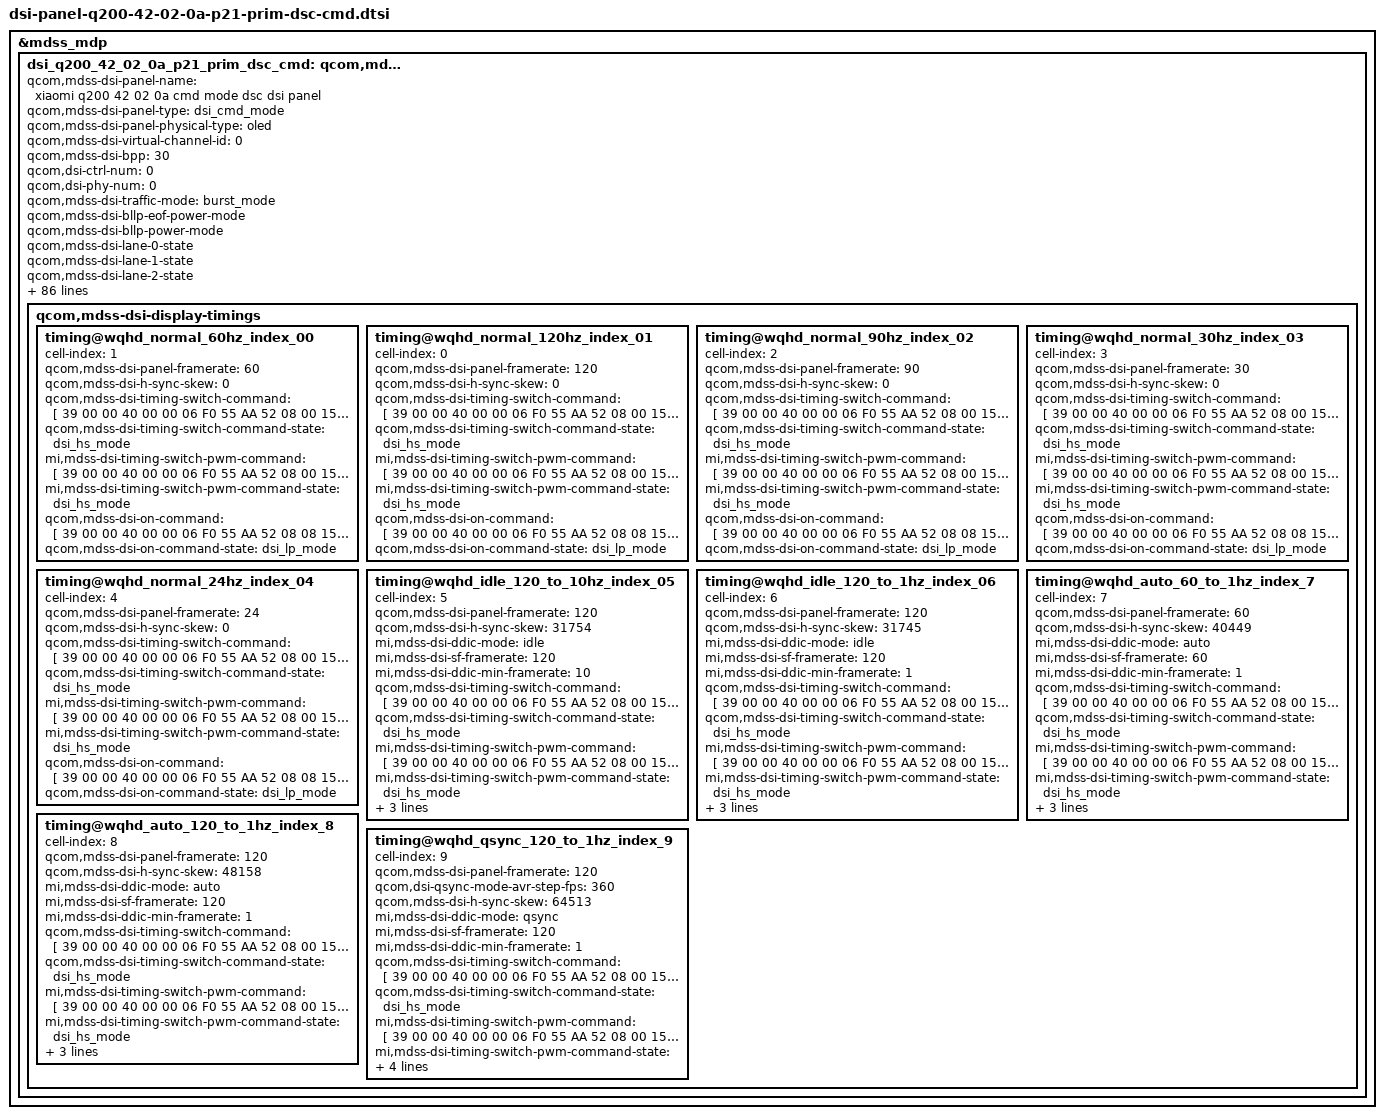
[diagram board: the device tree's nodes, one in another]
&mdss_mdp {
	dsi_q200_42_02_0a_p21_prim_dsc_cmd: qcom,mdss_dsi_q200_42_02_0a_p21_prim_dsc_cmd {
		qcom,mdss-dsi-panel-name = "xiaomi q200 42 02 0a cmd mode dsc dsi panel";
		qcom,mdss-dsi-panel-type = "dsi_cmd_mode";
		qcom,mdss-dsi-panel-physical-type = "oled";
		qcom,mdss-dsi-virtual-channel-id = <0>;
		qcom,mdss-dsi-bpp = <30>;
		qcom,dsi-ctrl-num = <0>;
		qcom,dsi-phy-num = <0>;
		qcom,mdss-dsi-traffic-mode = "burst_mode";
		qcom,mdss-dsi-bllp-eof-power-mode;
		qcom,mdss-dsi-bllp-power-mode;
		qcom,mdss-dsi-lane-0-state;
		qcom,mdss-dsi-lane-1-state;
		qcom,mdss-dsi-lane-2-state;
		qcom,mdss-dsi-lane-3-state;
		qcom,mdss-dsi-color-order = "rgb_swap_rgb";
		qcom,mdss-dsi-dma-trigger = "trigger_sw";
		qcom,mdss-dsi-mdp-trigger = "none";
		qcom,mdss-dsi-reset-sequence =<1 1>, <0 1>, <1 10>;
		qcom,mdss-pan-physical-width-dimension = <673>;
		qcom,mdss-pan-physical-height-dimension = <1466>;
		qcom,mdss-dsi-te-pin-select = <1>;
		qcom,mdss-dsi-wr-mem-start = <0x2c>;
		qcom,mdss-dsi-wr-mem-continue = <0x3c>;
		qcom,mdss-dsi-te-dcs-command = <1>;
		qcom,mdss-dsi-tx-eot-append;
		qcom,mdss-dsi-lp11-init;
		qcom,mdss-dsi-bl-inverted-dbv;
		qcom,bl-update-flag = "delay_until_first_frame";
		qcom,mdss-dsi-panel-hdr-enabled;
		qcom,mdss-dsi-panel-hdr-color-primaries = <14500 15500 32000
			17000 15500 30000 8000 3000>;
		qcom,mdss-dsi-panel-peak-brightness = <32000000>;
		qcom,mdss-dsi-panel-blackness-level = <3230>;
		qcom,mdss-dsi-dma-schedule-line = <1>;
		qcom,mdss-dsi-dma-schedule-window = <50>;

		qcom,spr-pack-type = "pentile";
		/*
		 *###############################################################
		 * # Pentile SPR phases for SM8850 and later
		 *###############################################################
		 * # RG/BG Type A    BG/RG Type A    GR/GB Type A    GB/GR Type A
		 * # R B R B ...     B R B R ...      R B R B ...     B R B R ...
		 * #  G G G G ...     G G G G ...    G G G G ...     G G G G ...
		 * #
		 * # RG/BG Type B    BG/RG Type B    GR/GB Type B    GB/GR Type B
		 * #  G G G G ...     G G G G ...    G G G G ...     G G G G ...
		 * # R B R B ...     B R B R ...      R B R B ...     B R B R ...
		 *###############################################################
		 */
		qcom,spr-pentile-pack-type = "BG-RG Type A";

		qcom,mdss-disable-cesta-hw-sleep;

		qcom,mdss-dsi-display-timings {
			timing@wqhd_normal_60hz_index_00 {
				#include "dsi-panel-q200-42-02-0a-p21-prim-dsc-cmd-common.dtsi"
				cell-index = <1>;
				qcom,mdss-dsi-panel-framerate = <60>;
				qcom,mdss-dsi-h-sync-skew = <0>;
				qcom,mdss-dsi-timing-switch-command = [
					// Fix 60hz Temp
					39 00 00 40 00 00 06 F0 55 AA 52 08 00
					15 00 00 40 00 00 02 6F 0E
					15 00 00 40 00 00 02 C0 00
					15 00 00 40 00 00 02 6F DE
					15 00 00 40 00 00 02 BA 04
					15 00 00 40 00 00 02 6F 04
					15 00 00 40 00 00 02 35 01
					15 00 00 40 00 00 02 6F 14
					15 00 00 40 00 00 02 35 00
					39 00 00 40 00 00 03 44 0A 60
					15 00 00 40 00 00 02 8C 02
					15 00 00 00 00 00 02 6D 02
				];
				qcom,mdss-dsi-timing-switch-command-state = "dsi_hs_mode";
				mi,mdss-dsi-timing-switch-pwm-command = [
					// Fix 60hz Temp
					39 00 00 40 00 00 06 F0 55 AA 52 08 00
					15 00 00 40 00 00 02 6F 0E
					15 00 00 40 00 00 02 C0 00
					15 00 00 40 00 00 02 6F DE
					15 00 00 40 00 00 02 BA 04
					15 00 00 40 00 00 02 6F 04
					15 00 00 40 00 00 02 35 01
					15 00 00 40 00 00 02 6F 14
					15 00 00 40 00 00 02 35 00
					39 00 00 40 00 00 03 44 0A 60
					15 00 00 40 00 00 02 8C 02
					15 00 00 00 00 00 02 6D 02
				];
				mi,mdss-dsi-timing-switch-pwm-command-state = "dsi_hs_mode";
				qcom,mdss-dsi-on-command = [
					// LCTC ON
					39 00 00 40 00 00 06 F0 55 AA 52 08 08
					15 00 00 40 00 00 02 BF 21
					// ACTC ON
					15 00 00 40 00 00 02 6F B7
					15 00 00 00 00 00 02 BF 11
					// OD ON
					39 00 00 40 00 00 06 F0 55 AA 52 08 08
					15 00 00 00 00 00 02 E0 01
					// VINT power domain
					39 00 00 40 00 00 06 F0 55 AA 52 08 01
					15 00 00 40 00 00 02 6F 49
					39 00 00 00 00 00 06 B9 01 22 00 EE EE
					// AOD pump
					39 00 00 40 00 00 06 F0 55 AA 52 08 01
					39 00 00 00 00 00 05 B2 00 00 FF 03
					// Data chopper setting
					39 00 00 40 00 00 06 F0 55 AA 52 08 01
					15 00 00 40 00 00 02 6F 23
					39 00 00 00 00 00 04 D9 CB 49 13
					// EM TH2 Duty Setting
					39 00 00 40 00 00 06 F0 55 AA 52 08 00
					39 00 00 40 00 00 02 6F 21
					39 00 00 40 00 00 09 B2 00 28 00 28 00 3C 00 28
					39 00 00 40 00 00 02 6F 75
					39 00 00 40 00 00 09 B2 00 28 00 28 00 3C 00 28
					39 00 00 40 00 00 02 6F 71
					39 00 00 00 00 00 03 B2 00 28
					// PMIC Fast discharge
					39 00 00 40 00 00 02 6F 51
					39 00 00 40 00 00 02 D5 02
					39 00 00 40 00 00 02 6F 54
					39 00 00 00 00 00 02 D5 1F
					// Switch VGMP by Fcon
					39 00 00 40 00 00 06 F0 55 AA 52 08 01
					39 00 00 40 00 00 02 6F 16
					39 00 00 00 00 00 05 C6 87 22 2C 2C
					// demura,FLASH CODE
					39 00 00 40 00 00 06 F0 55 AA 52 08 00
					39 00 00 40 00 00 02 C7 44
					39 00 00 40 00 00 02 6F 31
					39 00 00 40 00 00 03 C0 00 20
					39 00 00 40 00 00 02 6F 06
					39 00 00 40 00 00 03 C7 60 60
					39 00 00 40 00 00 02 6F 08
					39 00 00 40 00 00 03 C7 66 26
					39 00 00 40 00 00 06 F0 55 AA 52 08 04
					39 00 00 00 00 00 02 C0 20
					// SVM
					39 00 00 40 00 00 06 F0 55 AA 52 08 00
					39 00 00 40 00 00 02 6F 20
					39 00 00 40 00 00 02 B2 03
					39 00 00 40 00 00 06 F0 55 AA 52 08 01
					39 00 00 40 00 00 02 6F F0
					39 00 00 40 00 00 02 C0 F1
					39 00 00 40 00 00 02 6F F1
					39 00 00 40 00 00 03 C0 12 12
					39 00 00 40 00 00 02 6F F4
					39 00 00 40 00 00 03 C0 12 12
					39 00 00 40 00 00 02 6F 01
					39 00 00 40 00 00 04 CE 00 00 00
					39 00 00 40 00 00 02 6F 94
					39 00 00 40 00 00 04 E2 00 11 00
					39 00 00 40 00 00 02 6F 24
					39 00 00 40 00 00 13 E5 42 8C 94 90 92 07 42 8C 94 90 92 07 42 8C 94 90 92 07
					39 00 00 40 00 00 02 6F A7
					39 00 00 40 00 00 02 E7 C0
					39 00 00 40 00 00 02 6F DA
					39 00 00 40 00 00 03 E7 00 00
					39 00 00 40 00 00 06 F0 55 AA 52 08 01
					39 00 00 40 00 00 02 6F E3
					39 00 00 00 00 00 18 E5 FF FF FF FF 9B 9B 61 61 4D 4D 3A 3A 00 00 00 00 00 00 00 00 00 00 00
					// APL,Normal 32,HBM 8,APL 0
					39 00 00 40 00 00 06 F0 55 AA 52 08 00
					39 00 00 40 00 00 02 6F 78
					39 00 00 40 00 00 18 B0 11 00 2A 00 C2 01 DA 03 7C 05 B1 08 80 0B EE 0F FF 05 55 05 56 05 55
					39 00 00 40 00 00 02 6F 6F
					39 00 00 40 00 00 07 B0 02 62 04 C4 02 62
					39 00 00 40 00 00 06 F0 55 AA 52 08 08
					39 00 00 40 00 00 17 C1 9C FF CC FF FF CC FF FF CC FF FF DC FF FF DD FF FF FF 7F FF 0E FF
					39 00 00 40 00 00 02 6F 1D
					39 00 00 40 00 00 07 C1 00 FF FF 4F 00 FF
					39 00 00 40 00 00 02 6F 23
					39 00 00 40 00 00 15 C1 0C FF CC FF FF CC FF FF CC FF FF DC FF FF DD FF FF CF 7F 67
					39 00 00 40 00 00 02 6F 37
					39 00 00 40 00 00 15 C1 0C FF CC FF FF CC FF FF CC FF FF DC FF FF DD FF FF FF 7F FF
					39 00 00 40 00 00 02 6F 4B
					39 00 00 00 00 00 15 C1 0C FF CC FF FF CC FF FF CC FF FF DC FF FF DD FF FF CF 7F 67
					// Data Scaling DBV_TH
					39 00 00 00 00 00 2D BA 00 07 00 26 00 26 00 64 00 64 00 AC 00 AC 01 26 01 26 02 5F 02 5F 02 60 02 60 07 FB 07 FB 17 FE 17 FE 1F FF 1F FF 34 BC 34 BC 3F FE
					// ESD ERR Flag
					39 00 00 40 00 00 06 F0 55 AA 52 08 00
					39 00 00 40 00 00 03 BE 47 45
					15 00 00 40 00 00 02 6F 05
					15 00 00 40 00 00 02 BE 00
					15 00 00 40 00 00 02 6F 19
					39 00 00 00 00 00 05 BE 10 0A 00 9C
					// DVDD Low Voltage detect
					39 00 00 40 00 00 06 F0 55 AA 52 08 01
					15 00 00 40 00 00 02 6F 03
					15 00 00 00 00 00 02 C7 C7
					// ESD protect
					39 00 00 40 00 00 05 FF AA 55 A5 81
					39 00 00 40 00 00 02 6F 0F
					39 00 00 00 00 00 02 FD 80
					// video trim
					39 00 00 40 00 00 06 F0 55 AA 52 08 01
					39 00 00 40 00 00 37 C3 DD 29 02 6F E3 00 29 00 6F E3 00 3F 49 2E 3F 26 0F 3F 49 2E
											3F 26 0F 3F 49 2E 3F 26 0F 3F 49 2E 3F 26 0F 3F 49 2E 3F 26 0F 11 11 01 11 11 01 77 C0 AA 02 AA 02 00
					39 00 00 00 00 00 24 EA 11 02 3C 00 0D 0B 0A 00 00 00 00 11 02 3C 00 0D 0B 0A 00 00
											00 00 00 00 00 00 00 00 00 00 00 0C 00 00 40
					// 1220*2656
					39 00 00 40 00 00 05 2A 00 00 04 C3
					39 00 00 00 00 00 05 2B 00 00 0A 5F
					// VESA Setting
					39 00 00 40 00 00 02 90 03
					39 00 00 40 00 00 02 6F 01
					39 00 00 40 00 00 02 90 43
					39 00 00 40 00 00 13 91 89 28 00 10 C2 00 02 32 01 9C 00 08 06 67 05 92 10 E0
					// DC 120Hz
					39 00 00 40 00 00 02 2F 30
					39 00 00 00 00 00 02 6D 00
					// TE On
					39 00 00 00 00 00 02 35 00
					// DBV = 0
					39 00 00 00 00 00 03 51 00 00
					// idle_dimming_dbv = 0
					39 00 00 40 00 00 02 6F 04
					39 00 00 00 00 00 03 51 00 00
					// BCTRL = 1, DD = 0
					39 00 00 00 00 00 02 53 20
					// 0x00 Data remap off 0x0F Data remap on
					39 00 00 40 00 00 06 F0 55 AA 52 08 00
					39 00 00 40 00 00 02 6F 02
					39 00 00 40 00 00 02 B2 0F
 					// Skip mode setting
					39 00 00 40 00 00 04 8C 00 00 10
					39 00 00 40 00 00 03 5A 00 00
					39 00 00 00 00 00 02 2F 30
					// AP SPR
					39 00 00 40 00 00 06 F0 55 AA 52 08 03
					39 00 00 40 00 00 02 6F 09
					39 00 00 40 00 00 07 DE 10 34 25 30 14 25
					39 00 00 40 00 00 06 F0 55 AA 52 08 07
					39 00 00 40 00 00 06 B0 84 44 00 00 40
					39 00 00 40 00 00 07 B1 18 08 00 08 18 00
					39 00 00 00 00 00 13 91 AB F0 00 10 C1 00 01 CB 00 73 00 33 06 67 1F B0 11 40
					// Fix 60hz Temp
					39 00 00 40 00 00 06 F0 55 AA 52 08 00
					15 00 00 40 00 00 02 6F 0E
					15 00 00 40 00 00 02 C0 00
					15 00 00 40 00 00 02 6F DE
					15 00 00 40 00 00 02 BA 04
					15 00 00 40 00 00 02 6F 04
					15 00 00 40 00 00 02 35 01
					15 00 00 40 00 00 02 6F 14
					15 00 00 40 00 00 02 35 00
					39 00 00 40 00 00 03 44 0A 60
					15 00 00 40 00 00 02 8C 02
					15 00 00 00 00 00 02 6D 02
					// Still = 0 VDO no RAM
					39 00 00 00 00 00 02 18 00
					// GPO2 = Vsync
					39 00 00 40 00 00 06 F0 55 AA 52 08 00
					39 00 00 40 00 00 02 6F 02
					39 00 00 40 00 00 03 BE 4F 4A
					39 00 00 40 00 00 02 6F 0A
					39 00 00 00 00 00 02 BE 02
					// VDO with RAM
					39 00 00 40 00 00 06 F0 55 AA 52 08 01
					39 00 00 40 00 00 02 6F 17
					39 00 00 00 00 00 02 B8 07
					// GMA By Frame
					39 00 00 40 00 00 06 F0 55 AA 52 08 02
					39 00 00 00 00 00 02 CC 10
					// Idle Mode porch
					39 00 00 40 00 00 05 FF AA 55 A5 81
					39 00 00 40 00 00 02 6F 0F
					39 00 00 00 00 00 02 F5 0E
					// Demura on
					39 00 00 40 00 00 06 F0 55 AA 52 08 04
					39 00 00 00 00 00 02 CA 01
					// A3 Setting
					39 00 00 40 00 00 06 F0 55 AA 52 08 04
					39 00 00 40 00 00 02 6F 06
					39 00 00 40 00 00 02 B5 00
					39 00 00 40 00 00 05 FF AA 55 A5 81
					39 00 00 40 00 00 02 6F 0D
					39 00 00 40 00 00 02 FD 40
					39 00 00 40 00 00 07 51 00 00 00 00 00 00
					39 00 00 00 00 00 06 A3 84 02 5F 02 5F
					// Sleep Out
					05 00 00 00 5F 00 01 11
					// expand demura lut 16DBV*7Gray
					39 00 00 40 00 00 13 A3 84 02 5F 02 5F 02 04 B5 02 03 00 03 00 00 00 00 00 00
					39 00 00 40 00 00 02 6F 12
					39 00 00 40 00 00 0E A3 01 00 9D 00 00 AA 00 00 00 00 00 00 00
					39 00 00 40 00 00 02 6F 53
					39 00 00 40 00 00 0E A3 02 04 B5 02 03 00 0C 00 00 00 00 00 00
					39 00 00 40 00 00 02 6F 60
					39 00 00 00 00 00 0E A3 01 00 9D 00 00 AA 00 00 00 00 00 00 00
					// Display On
					05 00 00 00 00 00 01 29
					// ESD ERR Flag on
					39 00 00 40 00 00 06 F0 55 AA 52 08 00
					15 00 00 40 00 00 02 6F 05
					15 00 00 00 00 00 02 BE 08
					//OD code
					39 00 00 40 00 00 06 F0 55 AA 52 08 08
					15 00 00 40 00 00 02 6F 1B
					39 00 00 40 00 00 07 EB 34 E0 00 05 00 00
					//120Hz DC Skip Frame Rate
					39 00 00 40 00 00 06 F0 55 AA 52 08 00
					15 00 00 40 00 00 02 6F 5A
					39 00 00 00 00 00 09 D1 10 10 00 00 00 01 20 21
				];
				qcom,mdss-dsi-on-command-state = "dsi_lp_mode";
			};
			timing@wqhd_normal_120hz_index_01 {
				#include "dsi-panel-q200-42-02-0a-p21-prim-dsc-cmd-common.dtsi"
				cell-index = <0>;
				qcom,mdss-dsi-panel-framerate = <120>;
				qcom,mdss-dsi-h-sync-skew = <0>;
				qcom,mdss-dsi-timing-switch-command = [
					// Fix 120hz Temp
					39 00 00 40 00 00 06 F0 55 AA 52 08 00
					15 00 00 40 00 00 02 6F 0E
					15 00 00 40 00 00 02 C0 00
					15 00 00 40 00 00 02 6F DE
					15 00 00 40 00 00 02 BA 04
					15 00 00 40 00 00 02 6F 04
					15 00 00 40 00 00 02 35 00
					15 00 00 40 00 00 02 6F 14
					15 00 00 40 00 00 02 35 00
					39 00 00 40 00 00 03 44 0A 60
					15 00 00 40 00 00 02 8C 02
					15 00 00 00 00 00 02 6D 00
				];
				qcom,mdss-dsi-timing-switch-command-state = "dsi_hs_mode";
				mi,mdss-dsi-timing-switch-pwm-command = [
					// Fix 120hz Temp
					39 00 00 40 00 00 06 F0 55 AA 52 08 00
					15 00 00 40 00 00 02 6F 0E
					15 00 00 40 00 00 02 C0 00
					15 00 00 40 00 00 02 6F DE
					15 00 00 40 00 00 02 BA 04
					15 00 00 40 00 00 02 6F 04
					15 00 00 40 00 00 02 35 00
					15 00 00 40 00 00 02 6F 14
					15 00 00 40 00 00 02 35 00
					39 00 00 40 00 00 03 44 0A 60
					15 00 00 40 00 00 02 8C 02
					15 00 00 00 00 00 02 6D 00
				];
				mi,mdss-dsi-timing-switch-pwm-command-state = "dsi_hs_mode";
				qcom,mdss-dsi-on-command = [
					// LCTC ON
					39 00 00 40 00 00 06 F0 55 AA 52 08 08
					15 00 00 40 00 00 02 BF 21
					// ACTC ON
					15 00 00 40 00 00 02 6F B7
					15 00 00 00 00 00 02 BF 11
					// OD ON
					39 00 00 40 00 00 06 F0 55 AA 52 08 08
					15 00 00 00 00 00 02 E0 01
					// VINT power domain
					39 00 00 40 00 00 06 F0 55 AA 52 08 01
					15 00 00 40 00 00 02 6F 49
					39 00 00 00 00 00 06 B9 01 22 00 EE EE
					// AOD pump
					39 00 00 40 00 00 06 F0 55 AA 52 08 01
					39 00 00 00 00 00 05 B2 00 00 FF 03
					// Data chopper setting
					39 00 00 40 00 00 06 F0 55 AA 52 08 01
					15 00 00 40 00 00 02 6F 23
					39 00 00 00 00 00 04 D9 CB 49 13
					// EM TH2 Duty Setting
					39 00 00 40 00 00 06 F0 55 AA 52 08 00
					39 00 00 40 00 00 02 6F 21
					39 00 00 40 00 00 09 B2 00 28 00 28 00 3C 00 28
					39 00 00 40 00 00 02 6F 75
					39 00 00 40 00 00 09 B2 00 28 00 28 00 3C 00 28
					39 00 00 40 00 00 02 6F 71
					39 00 00 00 00 00 03 B2 00 28
					// PMIC Fast discharge
					39 00 00 40 00 00 02 6F 51
					39 00 00 40 00 00 02 D5 02
					39 00 00 40 00 00 02 6F 54
					39 00 00 00 00 00 02 D5 1F
					// Switch VGMP by Fcon
					39 00 00 40 00 00 06 F0 55 AA 52 08 01
					39 00 00 40 00 00 02 6F 16
					39 00 00 00 00 00 05 C6 87 22 2C 2C
					// demura,FLASH CODE
					39 00 00 40 00 00 06 F0 55 AA 52 08 00
					39 00 00 40 00 00 02 C7 44
					39 00 00 40 00 00 02 6F 31
					39 00 00 40 00 00 03 C0 00 20
					39 00 00 40 00 00 02 6F 06
					39 00 00 40 00 00 03 C7 60 60
					39 00 00 40 00 00 02 6F 08
					39 00 00 40 00 00 03 C7 66 26
					39 00 00 40 00 00 06 F0 55 AA 52 08 04
					39 00 00 00 00 00 02 C0 20
					// SVM
					39 00 00 40 00 00 06 F0 55 AA 52 08 00
					39 00 00 40 00 00 02 6F 20
					39 00 00 40 00 00 02 B2 03
					39 00 00 40 00 00 06 F0 55 AA 52 08 01
					39 00 00 40 00 00 02 6F F0
					39 00 00 40 00 00 02 C0 F1
					39 00 00 40 00 00 02 6F F1
					39 00 00 40 00 00 03 C0 12 12
					39 00 00 40 00 00 02 6F F4
					39 00 00 40 00 00 03 C0 12 12
					39 00 00 40 00 00 02 6F 01
					39 00 00 40 00 00 04 CE 00 00 00
					39 00 00 40 00 00 02 6F 94
					39 00 00 40 00 00 04 E2 00 11 00
					39 00 00 40 00 00 02 6F 24
					39 00 00 40 00 00 13 E5 42 8C 94 90 92 07 42 8C 94 90 92 07 42 8C 94 90 92 07
					39 00 00 40 00 00 02 6F A7
					39 00 00 40 00 00 02 E7 C0
					39 00 00 40 00 00 02 6F DA
					39 00 00 40 00 00 03 E7 00 00
					39 00 00 40 00 00 06 F0 55 AA 52 08 01
					39 00 00 40 00 00 02 6F E3
					39 00 00 00 00 00 18 E5 FF FF FF FF 9B 9B 61 61 4D 4D 3A 3A 00 00 00 00 00 00 00 00 00 00 00
					// APL,Normal 32,HBM 8,APL 0
					39 00 00 40 00 00 06 F0 55 AA 52 08 00
					39 00 00 40 00 00 02 6F 78
					39 00 00 40 00 00 18 B0 11 00 2A 00 C2 01 DA 03 7C 05 B1 08 80 0B EE 0F FF 05 55 05 56 05 55
					39 00 00 40 00 00 02 6F 6F
					39 00 00 40 00 00 07 B0 02 62 04 C4 02 62
					39 00 00 40 00 00 06 F0 55 AA 52 08 08
					39 00 00 40 00 00 17 C1 9C FF CC FF FF CC FF FF CC FF FF DC FF FF DD FF FF FF 7F FF 0E FF
					39 00 00 40 00 00 02 6F 1D
					39 00 00 40 00 00 07 C1 00 FF FF 4F 00 FF
					39 00 00 40 00 00 02 6F 23
					39 00 00 40 00 00 15 C1 0C FF CC FF FF CC FF FF CC FF FF DC FF FF DD FF FF CF 7F 67
					39 00 00 40 00 00 02 6F 37
					39 00 00 40 00 00 15 C1 0C FF CC FF FF CC FF FF CC FF FF DC FF FF DD FF FF FF 7F FF
					39 00 00 40 00 00 02 6F 4B
					39 00 00 00 00 00 15 C1 0C FF CC FF FF CC FF FF CC FF FF DC FF FF DD FF FF CF 7F 67
					// Data Scaling DBV_TH
					39 00 00 00 00 00 2D BA 00 07 00 26 00 26 00 64 00 64 00 AC 00 AC 01 26 01 26 02 5F 02 5F 02 60 02 60 07 FB 07 FB 17 FE 17 FE 1F FF 1F FF 34 BC 34 BC 3F FE
					// ESD ERR Flag
					39 00 00 40 00 00 06 F0 55 AA 52 08 00
					39 00 00 40 00 00 03 BE 47 45
					15 00 00 40 00 00 02 6F 05
					15 00 00 40 00 00 02 BE 00
					15 00 00 40 00 00 02 6F 19
					39 00 00 00 00 00 05 BE 10 0A 00 9C
					// DVDD Low Voltage detect
					39 00 00 40 00 00 06 F0 55 AA 52 08 01
					15 00 00 40 00 00 02 6F 03
					15 00 00 00 00 00 02 C7 C7
					// ESD protect
					39 00 00 40 00 00 05 FF AA 55 A5 81
					39 00 00 40 00 00 02 6F 0F
					39 00 00 00 00 00 02 FD 80
					// video trim
					39 00 00 40 00 00 06 F0 55 AA 52 08 01
					39 00 00 40 00 00 37 C3 DD 29 02 6F E3 00 29 00 6F E3 00 3F 49 2E 3F 26 0F 3F 49 2E
											3F 26 0F 3F 49 2E 3F 26 0F 3F 49 2E 3F 26 0F 3F 49 2E 3F 26 0F 11 11 01 11 11 01 77 C0 AA 02 AA 02 00
					39 00 00 00 00 00 24 EA 11 02 3C 00 0D 0B 0A 00 00 00 00 11 02 3C 00 0D 0B 0A 00 00
											00 00 00 00 00 00 00 00 00 00 00 0C 00 00 40
					// 1220*2656
					39 00 00 40 00 00 05 2A 00 00 04 C3
					39 00 00 00 00 00 05 2B 00 00 0A 5F
					// VESA Setting
					39 00 00 40 00 00 02 90 03
					39 00 00 40 00 00 02 6F 01
					39 00 00 40 00 00 02 90 43
					39 00 00 40 00 00 13 91 89 28 00 10 C2 00 02 32 01 9C 00 08 06 67 05 92 10 E0
					// DC 120Hz
					39 00 00 40 00 00 02 2F 30
					39 00 00 00 00 00 02 6D 00
					// TE On
					39 00 00 00 00 00 02 35 00
					// DBV = 0
					39 00 00 00 00 00 03 51 00 00
					// idle_dimming_dbv = 0
					39 00 00 40 00 00 02 6F 04
					39 00 00 00 00 00 03 51 00 00
					// BCTRL = 1, DD = 0
					39 00 00 00 00 00 02 53 20
					// 0x00 Data remap off 0x0F Data remap on
					39 00 00 40 00 00 06 F0 55 AA 52 08 00
					39 00 00 40 00 00 02 6F 02
					39 00 00 40 00 00 02 B2 0F
 					// Skip mode setting
					39 00 00 40 00 00 04 8C 00 00 10
					39 00 00 40 00 00 03 5A 00 00
					39 00 00 00 00 00 02 2F 30
					// AP SPR
					39 00 00 40 00 00 06 F0 55 AA 52 08 03
					39 00 00 40 00 00 02 6F 09
					39 00 00 40 00 00 07 DE 10 34 25 30 14 25
					39 00 00 40 00 00 06 F0 55 AA 52 08 07
					39 00 00 40 00 00 06 B0 84 44 00 00 40
					39 00 00 40 00 00 07 B1 18 08 00 08 18 00
					39 00 00 00 00 00 13 91 AB F0 00 10 C1 00 01 CB 00 73 00 33 06 67 1F B0 11 40
					// Fix 120hz Temp
					39 00 00 40 00 00 06 F0 55 AA 52 08 00
					15 00 00 40 00 00 02 6F 0E
					15 00 00 40 00 00 02 C0 00
					15 00 00 40 00 00 02 6F DE
					15 00 00 40 00 00 02 BA 04
					15 00 00 40 00 00 02 6F 04
					15 00 00 40 00 00 02 35 00
					15 00 00 40 00 00 02 6F 14
					15 00 00 40 00 00 02 35 00
					39 00 00 40 00 00 03 44 0A 60
					15 00 00 40 00 00 02 8C 02
					15 00 00 00 00 00 02 6D 00
					// Still = 0 VDO no RAM
					39 00 00 00 00 00 02 18 00
					// GPO2 = Vsync
					39 00 00 40 00 00 06 F0 55 AA 52 08 00
					39 00 00 40 00 00 02 6F 02
					39 00 00 40 00 00 03 BE 4F 4A
					39 00 00 40 00 00 02 6F 0A
					39 00 00 00 00 00 02 BE 02
					// VDO with RAM
					39 00 00 40 00 00 06 F0 55 AA 52 08 01
					39 00 00 40 00 00 02 6F 17
					39 00 00 00 00 00 02 B8 07
					// GMA By Frame
					39 00 00 40 00 00 06 F0 55 AA 52 08 02
					39 00 00 00 00 00 02 CC 10
					// Idle Mode porch
					39 00 00 40 00 00 05 FF AA 55 A5 81
					39 00 00 40 00 00 02 6F 0F
					39 00 00 00 00 00 02 F5 0E
					// Demura on
					39 00 00 40 00 00 06 F0 55 AA 52 08 04
					39 00 00 00 00 00 02 CA 01
					// A3 Setting
					39 00 00 40 00 00 06 F0 55 AA 52 08 04
					39 00 00 40 00 00 02 6F 06
					39 00 00 40 00 00 02 B5 00
					39 00 00 40 00 00 05 FF AA 55 A5 81
					39 00 00 40 00 00 02 6F 0D
					39 00 00 40 00 00 02 FD 40
					39 00 00 40 00 00 07 51 00 00 00 00 00 00
					39 00 00 00 00 00 06 A3 84 02 5F 02 5F
					// Sleep Out
					05 00 00 00 5F 00 01 11
					// expand demura lut 16DBV*7Gray
					39 00 00 40 00 00 13 A3 84 02 5F 02 5F 02 04 B5 02 03 00 03 00 00 00 00 00 00
					39 00 00 40 00 00 02 6F 12
					39 00 00 40 00 00 0E A3 01 00 9D 00 00 AA 00 00 00 00 00 00 00
					39 00 00 40 00 00 02 6F 53
					39 00 00 40 00 00 0E A3 02 04 B5 02 03 00 0C 00 00 00 00 00 00
					39 00 00 40 00 00 02 6F 60
					39 00 00 00 00 00 0E A3 01 00 9D 00 00 AA 00 00 00 00 00 00 00
					// Display On
					05 00 00 00 00 00 01 29
					// ESD ERR Flag on
					39 00 00 40 00 00 06 F0 55 AA 52 08 00
					15 00 00 40 00 00 02 6F 05
					15 00 00 00 00 00 02 BE 08
					//OD code
					39 00 00 40 00 00 06 F0 55 AA 52 08 08
					15 00 00 40 00 00 02 6F 1B
					39 00 00 40 00 00 07 EB 34 E0 00 05 00 00
					//120Hz DC Skip Frame Rate
					39 00 00 40 00 00 06 F0 55 AA 52 08 00
					15 00 00 40 00 00 02 6F 5A
					39 00 00 00 00 00 09 D1 10 10 00 00 00 01 20 21
				];
				qcom,mdss-dsi-on-command-state = "dsi_lp_mode";
			};
			timing@wqhd_normal_90hz_index_02 {
				#include "dsi-panel-q200-42-02-0a-p21-prim-dsc-cmd-common.dtsi"
				cell-index = <2>;
				qcom,mdss-dsi-panel-framerate = <90>;
				qcom,mdss-dsi-h-sync-skew = <0>;
				qcom,mdss-dsi-timing-switch-command = [
					// AUTO 90hz Temp
					39 00 00 40 00 00 06 F0 55 AA 52 08 00
					15 00 00 40 00 00 02 6F 0E
					15 00 00 40 00 00 02 C0 01
					15 00 00 40 00 00 02 6F DE
					15 00 00 40 00 00 02 BA 00
					15 00 00 40 00 00 02 6F 04
					15 00 00 40 00 00 02 35 00
					15 00 00 40 00 00 02 6F 14
					15 00 00 40 00 00 02 35 00
					39 00 00 40 00 00 03 44 0D F0
					15 00 00 40 00 00 02 8C 00
					15 00 00 00 00 00 02 6D 0A
				];
				qcom,mdss-dsi-timing-switch-command-state = "dsi_hs_mode";
				mi,mdss-dsi-timing-switch-pwm-command = [
					// AUTO 90hz Temp
					39 00 00 40 00 00 06 F0 55 AA 52 08 00
					15 00 00 40 00 00 02 6F 0E
					15 00 00 40 00 00 02 C0 01
					15 00 00 40 00 00 02 6F DE
					15 00 00 40 00 00 02 BA 00
					15 00 00 40 00 00 02 6F 04
					15 00 00 40 00 00 02 35 00
					15 00 00 40 00 00 02 6F 14
					15 00 00 40 00 00 02 35 00
					39 00 00 40 00 00 03 44 0D F0
					15 00 00 40 00 00 02 8C 00
					15 00 00 00 00 00 02 6D 0A
				];
				mi,mdss-dsi-timing-switch-pwm-command-state = "dsi_hs_mode";
				qcom,mdss-dsi-on-command = [
					// LCTC ON
					39 00 00 40 00 00 06 F0 55 AA 52 08 08
					15 00 00 40 00 00 02 BF 21
					// ACTC ON
					15 00 00 40 00 00 02 6F B7
					15 00 00 00 00 00 02 BF 11
					// OD ON
					39 00 00 40 00 00 06 F0 55 AA 52 08 08
					15 00 00 00 00 00 02 E0 01
					// VINT power domain
					39 00 00 40 00 00 06 F0 55 AA 52 08 01
					15 00 00 40 00 00 02 6F 49
					39 00 00 00 00 00 06 B9 01 22 00 EE EE
					// AOD pump
					39 00 00 40 00 00 06 F0 55 AA 52 08 01
					39 00 00 00 00 00 05 B2 00 00 FF 03
					// Data chopper setting
					39 00 00 40 00 00 06 F0 55 AA 52 08 01
					15 00 00 40 00 00 02 6F 23
					39 00 00 00 00 00 04 D9 CB 49 13
					// EM TH2 Duty Setting
					39 00 00 40 00 00 06 F0 55 AA 52 08 00
					39 00 00 40 00 00 02 6F 21
					39 00 00 40 00 00 09 B2 00 28 00 28 00 3C 00 28
					39 00 00 40 00 00 02 6F 75
					39 00 00 40 00 00 09 B2 00 28 00 28 00 3C 00 28
					39 00 00 40 00 00 02 6F 71
					39 00 00 00 00 00 03 B2 00 28
					// PMIC Fast discharge
					39 00 00 40 00 00 02 6F 51
					39 00 00 40 00 00 02 D5 02
					39 00 00 40 00 00 02 6F 54
					39 00 00 00 00 00 02 D5 1F
					// Switch VGMP by Fcon
					39 00 00 40 00 00 06 F0 55 AA 52 08 01
					39 00 00 40 00 00 02 6F 16
					39 00 00 00 00 00 05 C6 87 22 2C 2C
					// demura,FLASH CODE
					39 00 00 40 00 00 06 F0 55 AA 52 08 00
					39 00 00 40 00 00 02 C7 44
					39 00 00 40 00 00 02 6F 31
					39 00 00 40 00 00 03 C0 00 20
					39 00 00 40 00 00 02 6F 06
					39 00 00 40 00 00 03 C7 60 60
					39 00 00 40 00 00 02 6F 08
					39 00 00 40 00 00 03 C7 66 26
					39 00 00 40 00 00 06 F0 55 AA 52 08 04
					39 00 00 00 00 00 02 C0 20
					// SVM
					39 00 00 40 00 00 06 F0 55 AA 52 08 00
					39 00 00 40 00 00 02 6F 20
					39 00 00 40 00 00 02 B2 03
					39 00 00 40 00 00 06 F0 55 AA 52 08 01
					39 00 00 40 00 00 02 6F F0
					39 00 00 40 00 00 02 C0 F1
					39 00 00 40 00 00 02 6F F1
					39 00 00 40 00 00 03 C0 12 12
					39 00 00 40 00 00 02 6F F4
					39 00 00 40 00 00 03 C0 12 12
					39 00 00 40 00 00 02 6F 01
					39 00 00 40 00 00 04 CE 00 00 00
					39 00 00 40 00 00 02 6F 94
					39 00 00 40 00 00 04 E2 00 11 00
					39 00 00 40 00 00 02 6F 24
					39 00 00 40 00 00 13 E5 42 8C 94 90 92 07 42 8C 94 90 92 07 42 8C 94 90 92 07
					39 00 00 40 00 00 02 6F A7
					39 00 00 40 00 00 02 E7 C0
					39 00 00 40 00 00 02 6F DA
					39 00 00 40 00 00 03 E7 00 00
					39 00 00 40 00 00 06 F0 55 AA 52 08 01
					39 00 00 40 00 00 02 6F E3
					39 00 00 00 00 00 18 E5 FF FF FF FF 9B 9B 61 61 4D 4D 3A 3A 00 00 00 00 00 00 00 00 00 00 00
					// APL,Normal 32,HBM 8,APL 0
					39 00 00 40 00 00 06 F0 55 AA 52 08 00
					39 00 00 40 00 00 02 6F 78
					39 00 00 40 00 00 18 B0 11 00 2A 00 C2 01 DA 03 7C 05 B1 08 80 0B EE 0F FF 05 55 05 56 05 55
					39 00 00 40 00 00 02 6F 6F
					39 00 00 40 00 00 07 B0 02 62 04 C4 02 62
					39 00 00 40 00 00 06 F0 55 AA 52 08 08
					39 00 00 40 00 00 17 C1 9C FF CC FF FF CC FF FF CC FF FF DC FF FF DD FF FF FF 7F FF 0E FF
					39 00 00 40 00 00 02 6F 1D
					39 00 00 40 00 00 07 C1 00 FF FF 4F 00 FF
					39 00 00 40 00 00 02 6F 23
					39 00 00 40 00 00 15 C1 0C FF CC FF FF CC FF FF CC FF FF DC FF FF DD FF FF CF 7F 67
					39 00 00 40 00 00 02 6F 37
					39 00 00 40 00 00 15 C1 0C FF CC FF FF CC FF FF CC FF FF DC FF FF DD FF FF FF 7F FF
					39 00 00 40 00 00 02 6F 4B
					39 00 00 00 00 00 15 C1 0C FF CC FF FF CC FF FF CC FF FF DC FF FF DD FF FF CF 7F 67
					// Data Scaling DBV_TH
					39 00 00 00 00 00 2D BA 00 07 00 26 00 26 00 64 00 64 00 AC 00 AC 01 26 01 26 02 5F 02 5F 02 60 02 60 07 FB 07 FB 17 FE 17 FE 1F FF 1F FF 34 BC 34 BC 3F FE
					// ESD ERR Flag
					39 00 00 40 00 00 06 F0 55 AA 52 08 00
					39 00 00 40 00 00 03 BE 47 45
					15 00 00 40 00 00 02 6F 05
					15 00 00 40 00 00 02 BE 00
					15 00 00 40 00 00 02 6F 19
					39 00 00 00 00 00 05 BE 10 0A 00 9C
					// DVDD Low Voltage detect
					39 00 00 40 00 00 06 F0 55 AA 52 08 01
					15 00 00 40 00 00 02 6F 03
					15 00 00 00 00 00 02 C7 C7
					// ESD protect
					39 00 00 40 00 00 05 FF AA 55 A5 81
					39 00 00 40 00 00 02 6F 0F
					39 00 00 00 00 00 02 FD 80
					// video trim
					39 00 00 40 00 00 06 F0 55 AA 52 08 01
					39 00 00 40 00 00 37 C3 DD 29 02 6F E3 00 29 00 6F E3 00 3F 49 2E 3F 26 0F 3F 49 2E
											3F 26 0F 3F 49 2E 3F 26 0F 3F 49 2E 3F 26 0F 3F 49 2E 3F 26 0F 11 11 01 11 11 01 77 C0 AA 02 AA 02 00
					39 00 00 00 00 00 24 EA 11 02 3C 00 0D 0B 0A 00 00 00 00 11 02 3C 00 0D 0B 0A 00 00
											00 00 00 00 00 00 00 00 00 00 00 0C 00 00 40
					// 1220*2656
					39 00 00 40 00 00 05 2A 00 00 04 C3
					39 00 00 00 00 00 05 2B 00 00 0A 5F
					// VESA Setting
					39 00 00 40 00 00 02 90 03
					39 00 00 40 00 00 02 6F 01
					39 00 00 40 00 00 02 90 43
					39 00 00 40 00 00 13 91 89 28 00 10 C2 00 02 32 01 9C 00 08 06 67 05 92 10 E0
					// DC 120Hz
					39 00 00 40 00 00 02 2F 30
					39 00 00 00 00 00 02 6D 00
					// TE On
					39 00 00 00 00 00 02 35 00
					// DBV = 0
					39 00 00 00 00 00 03 51 00 00
					// idle_dimming_dbv = 0
					39 00 00 40 00 00 02 6F 04
					39 00 00 00 00 00 03 51 00 00
					// BCTRL = 1, DD = 0
					39 00 00 00 00 00 02 53 20
					// 0x00 Data remap off 0x0F Data remap on
					39 00 00 40 00 00 06 F0 55 AA 52 08 00
					39 00 00 40 00 00 02 6F 02
					39 00 00 40 00 00 02 B2 0F
 					// Skip mode setting
					39 00 00 40 00 00 04 8C 00 00 10
					39 00 00 40 00 00 03 5A 00 00
					39 00 00 00 00 00 02 2F 30
					// AP SPR
					39 00 00 40 00 00 06 F0 55 AA 52 08 03
					39 00 00 40 00 00 02 6F 09
					39 00 00 40 00 00 07 DE 10 34 25 30 14 25
					39 00 00 40 00 00 06 F0 55 AA 52 08 07
					39 00 00 40 00 00 06 B0 84 44 00 00 40
					39 00 00 40 00 00 07 B1 18 08 00 08 18 00
					39 00 00 00 00 00 13 91 AB F0 00 10 C1 00 01 CB 00 73 00 33 06 67 1F B0 11 40
					// AUTO 90hz Temp
					39 00 00 40 00 00 06 F0 55 AA 52 08 00
					15 00 00 40 00 00 02 6F 0E
					15 00 00 40 00 00 02 C0 01
					15 00 00 40 00 00 02 6F DE
					15 00 00 40 00 00 02 BA 00
					15 00 00 40 00 00 02 6F 04
					15 00 00 40 00 00 02 35 00
					15 00 00 40 00 00 02 6F 14
					15 00 00 40 00 00 02 35 00
					39 00 00 40 00 00 03 44 0D F0
					15 00 00 40 00 00 02 8C 00
					15 00 00 00 00 00 02 6D 0A
					// Still = 0 VDO no RAM
					39 00 00 00 00 00 02 18 00
					// GPO2 = Vsync
					39 00 00 40 00 00 06 F0 55 AA 52 08 00
					39 00 00 40 00 00 02 6F 02
					39 00 00 40 00 00 03 BE 4F 4A
					39 00 00 40 00 00 02 6F 0A
					39 00 00 00 00 00 02 BE 02
					// VDO with RAM
					39 00 00 40 00 00 06 F0 55 AA 52 08 01
					39 00 00 40 00 00 02 6F 17
					39 00 00 00 00 00 02 B8 07
					// GMA By Frame
					39 00 00 40 00 00 06 F0 55 AA 52 08 02
					39 00 00 00 00 00 02 CC 10
					// Idle Mode porch
					39 00 00 40 00 00 05 FF AA 55 A5 81
					39 00 00 40 00 00 02 6F 0F
					39 00 00 00 00 00 02 F5 0E
					// Demura on
					39 00 00 40 00 00 06 F0 55 AA 52 08 04
					39 00 00 00 00 00 02 CA 01
					// A3 Setting
					39 00 00 40 00 00 06 F0 55 AA 52 08 04
					39 00 00 40 00 00 02 6F 06
					39 00 00 40 00 00 02 B5 00
					39 00 00 40 00 00 05 FF AA 55 A5 81
					39 00 00 40 00 00 02 6F 0D
					39 00 00 40 00 00 02 FD 40
					39 00 00 40 00 00 07 51 00 00 00 00 00 00
					39 00 00 00 00 00 06 A3 84 02 5F 02 5F
					// Sleep Out
					05 00 00 00 5F 00 01 11
					// expand demura lut 16DBV*7Gray
					39 00 00 40 00 00 13 A3 84 02 5F 02 5F 02 04 B5 02 03 00 03 00 00 00 00 00 00
					39 00 00 40 00 00 02 6F 12
					39 00 00 40 00 00 0E A3 01 00 9D 00 00 AA 00 00 00 00 00 00 00
					39 00 00 40 00 00 02 6F 53
					39 00 00 40 00 00 0E A3 02 04 B5 02 03 00 0C 00 00 00 00 00 00
					39 00 00 40 00 00 02 6F 60
					39 00 00 00 00 00 0E A3 01 00 9D 00 00 AA 00 00 00 00 00 00 00
					// Display On
					05 00 00 00 00 00 01 29
					// ESD ERR Flag on
					39 00 00 40 00 00 06 F0 55 AA 52 08 00
					15 00 00 40 00 00 02 6F 05
					15 00 00 00 00 00 02 BE 08
					//OD code
					39 00 00 40 00 00 06 F0 55 AA 52 08 08
					15 00 00 40 00 00 02 6F 1B
					39 00 00 40 00 00 07 EB 34 E0 00 05 00 00
					//120Hz DC Skip Frame Rate
					39 00 00 40 00 00 06 F0 55 AA 52 08 00
					15 00 00 40 00 00 02 6F 5A
					39 00 00 00 00 00 09 D1 10 10 00 00 00 01 20 21
				];
				qcom,mdss-dsi-on-command-state = "dsi_lp_mode";
			};
			timing@wqhd_normal_30hz_index_03 {
				#include "dsi-panel-q200-42-02-0a-p21-prim-dsc-cmd-common.dtsi"
				cell-index = <3>;
				qcom,mdss-dsi-panel-framerate = <30>;
				qcom,mdss-dsi-h-sync-skew = <0>;
				qcom,mdss-dsi-timing-switch-command = [
					// Fix 30hz Temp
					39 00 00 40 00 00 06 F0 55 AA 52 08 00
					15 00 00 40 00 00 02 6F 0E
					15 00 00 40 00 00 02 C0 00
					15 00 00 40 00 00 02 6F DE
					15 00 00 40 00 00 02 BA 04
					15 00 00 40 00 00 02 6F 04
					15 00 00 40 00 00 02 35 03
					15 00 00 40 00 00 02 6F 14
					15 00 00 40 00 00 02 35 00
					39 00 00 40 00 00 03 44 0A 60
					15 00 00 40 00 00 02 8C 02
					15 00 00 00 00 00 02 6D 04
				];
				qcom,mdss-dsi-timing-switch-command-state = "dsi_hs_mode";
				mi,mdss-dsi-timing-switch-pwm-command = [
					// Fix 30hz Temp
					39 00 00 40 00 00 06 F0 55 AA 52 08 00
					15 00 00 40 00 00 02 6F 0E
					15 00 00 40 00 00 02 C0 00
					15 00 00 40 00 00 02 6F DE
					15 00 00 40 00 00 02 BA 04
					15 00 00 40 00 00 02 6F 04
					15 00 00 40 00 00 02 35 03
					15 00 00 40 00 00 02 6F 14
					15 00 00 40 00 00 02 35 00
					39 00 00 40 00 00 03 44 0A 60
					15 00 00 40 00 00 02 8C 02
					15 00 00 00 00 00 02 6D 04
				];
				mi,mdss-dsi-timing-switch-pwm-command-state = "dsi_hs_mode";
				qcom,mdss-dsi-on-command = [
					// LCTC ON
					39 00 00 40 00 00 06 F0 55 AA 52 08 08
					15 00 00 40 00 00 02 BF 21
					// ACTC ON
					15 00 00 40 00 00 02 6F B7
					15 00 00 00 00 00 02 BF 11
					// OD ON
					39 00 00 40 00 00 06 F0 55 AA 52 08 08
					15 00 00 00 00 00 02 E0 01
					// VINT power domain
					39 00 00 40 00 00 06 F0 55 AA 52 08 01
					15 00 00 40 00 00 02 6F 49
					39 00 00 00 00 00 06 B9 01 22 00 EE EE
					// AOD pump
					39 00 00 40 00 00 06 F0 55 AA 52 08 01
					39 00 00 00 00 00 05 B2 00 00 FF 03
					// Data chopper setting
					39 00 00 40 00 00 06 F0 55 AA 52 08 01
					15 00 00 40 00 00 02 6F 23
					39 00 00 00 00 00 04 D9 CB 49 13
					// EM TH2 Duty Setting
					39 00 00 40 00 00 06 F0 55 AA 52 08 00
					39 00 00 40 00 00 02 6F 21
					39 00 00 40 00 00 09 B2 00 28 00 28 00 3C 00 28
					39 00 00 40 00 00 02 6F 75
					39 00 00 40 00 00 09 B2 00 28 00 28 00 3C 00 28
					39 00 00 40 00 00 02 6F 71
					39 00 00 00 00 00 03 B2 00 28
					// PMIC Fast discharge
					39 00 00 40 00 00 02 6F 51
					39 00 00 40 00 00 02 D5 02
					39 00 00 40 00 00 02 6F 54
					39 00 00 00 00 00 02 D5 1F
					// Switch VGMP by Fcon
					39 00 00 40 00 00 06 F0 55 AA 52 08 01
					39 00 00 40 00 00 02 6F 16
					39 00 00 00 00 00 05 C6 87 22 2C 2C
					// demura,FLASH CODE
					39 00 00 40 00 00 06 F0 55 AA 52 08 00
					39 00 00 40 00 00 02 C7 44
					39 00 00 40 00 00 02 6F 31
					39 00 00 40 00 00 03 C0 00 20
					39 00 00 40 00 00 02 6F 06
					39 00 00 40 00 00 03 C7 60 60
					39 00 00 40 00 00 02 6F 08
					39 00 00 40 00 00 03 C7 66 26
					39 00 00 40 00 00 06 F0 55 AA 52 08 04
					39 00 00 00 00 00 02 C0 20
					// SVM
					39 00 00 40 00 00 06 F0 55 AA 52 08 00
					39 00 00 40 00 00 02 6F 20
					39 00 00 40 00 00 02 B2 03
					39 00 00 40 00 00 06 F0 55 AA 52 08 01
					39 00 00 40 00 00 02 6F F0
					39 00 00 40 00 00 02 C0 F1
					39 00 00 40 00 00 02 6F F1
					39 00 00 40 00 00 03 C0 12 12
					39 00 00 40 00 00 02 6F F4
					39 00 00 40 00 00 03 C0 12 12
					39 00 00 40 00 00 02 6F 01
					39 00 00 40 00 00 04 CE 00 00 00
					39 00 00 40 00 00 02 6F 94
					39 00 00 40 00 00 04 E2 00 11 00
					39 00 00 40 00 00 02 6F 24
					39 00 00 40 00 00 13 E5 42 8C 94 90 92 07 42 8C 94 90 92 07 42 8C 94 90 92 07
					39 00 00 40 00 00 02 6F A7
					39 00 00 40 00 00 02 E7 C0
					39 00 00 40 00 00 02 6F DA
					39 00 00 40 00 00 03 E7 00 00
					39 00 00 40 00 00 06 F0 55 AA 52 08 01
					39 00 00 40 00 00 02 6F E3
					39 00 00 00 00 00 18 E5 FF FF FF FF 9B 9B 61 61 4D 4D 3A 3A 00 00 00 00 00 00 00 00 00 00 00
					// APL,Normal 32,HBM 8,APL 0
					39 00 00 40 00 00 06 F0 55 AA 52 08 00
					39 00 00 40 00 00 02 6F 78
					39 00 00 40 00 00 18 B0 11 00 2A 00 C2 01 DA 03 7C 05 B1 08 80 0B EE 0F FF 05 55 05 56 05 55
					39 00 00 40 00 00 02 6F 6F
					39 00 00 40 00 00 07 B0 02 62 04 C4 02 62
					39 00 00 40 00 00 06 F0 55 AA 52 08 08
					39 00 00 40 00 00 17 C1 9C FF CC FF FF CC FF FF CC FF FF DC FF FF DD FF FF FF 7F FF 0E FF
					39 00 00 40 00 00 02 6F 1D
					39 00 00 40 00 00 07 C1 00 FF FF 4F 00 FF
					39 00 00 40 00 00 02 6F 23
					39 00 00 40 00 00 15 C1 0C FF CC FF FF CC FF FF CC FF FF DC FF FF DD FF FF CF 7F 67
					39 00 00 40 00 00 02 6F 37
					39 00 00 40 00 00 15 C1 0C FF CC FF FF CC FF FF CC FF FF DC FF FF DD FF FF FF 7F FF
					39 00 00 40 00 00 02 6F 4B
					39 00 00 00 00 00 15 C1 0C FF CC FF FF CC FF FF CC FF FF DC FF FF DD FF FF CF 7F 67
					// Data Scaling DBV_TH
					39 00 00 00 00 00 2D BA 00 07 00 26 00 26 00 64 00 64 00 AC 00 AC 01 26 01 26 02 5F 02 5F 02 60 02 60 07 FB 07 FB 17 FE 17 FE 1F FF 1F FF 34 BC 34 BC 3F FE
					// ESD ERR Flag
					39 00 00 40 00 00 06 F0 55 AA 52 08 00
					39 00 00 40 00 00 03 BE 47 45
					15 00 00 40 00 00 02 6F 05
					15 00 00 40 00 00 02 BE 00
					15 00 00 40 00 00 02 6F 19
					39 00 00 00 00 00 05 BE 10 0A 00 9C
					// DVDD Low Voltage detect
					39 00 00 40 00 00 06 F0 55 AA 52 08 01
					15 00 00 40 00 00 02 6F 03
					15 00 00 00 00 00 02 C7 C7
					// ESD protect
					39 00 00 40 00 00 05 FF AA 55 A5 81
					39 00 00 40 00 00 02 6F 0F
					39 00 00 00 00 00 02 FD 80
					// video trim
					39 00 00 40 00 00 06 F0 55 AA 52 08 01
					39 00 00 40 00 00 37 C3 DD 29 02 6F E3 00 29 00 6F E3 00 3F 49 2E 3F 26 0F 3F 49 2E
											3F 26 0F 3F 49 2E 3F 26 0F 3F 49 2E 3F 26 0F 3F 49 2E 3F 26 0F 11 11 01 11 11 01 77 C0 AA 02 AA 02 00
					39 00 00 00 00 00 24 EA 11 02 3C 00 0D 0B 0A 00 00 00 00 11 02 3C 00 0D 0B 0A 00 00
											00 00 00 00 00 00 00 00 00 00 00 0C 00 00 40
					// 1220*2656
					39 00 00 40 00 00 05 2A 00 00 04 C3
					39 00 00 00 00 00 05 2B 00 00 0A 5F
					// VESA Setting
					39 00 00 40 00 00 02 90 03
					39 00 00 40 00 00 02 6F 01
					39 00 00 40 00 00 02 90 43
					39 00 00 40 00 00 13 91 89 28 00 10 C2 00 02 32 01 9C 00 08 06 67 05 92 10 E0
					// DC 120Hz
					39 00 00 40 00 00 02 2F 30
					39 00 00 00 00 00 02 6D 00
					// TE On
					39 00 00 00 00 00 02 35 00
					// DBV = 0
					39 00 00 00 00 00 03 51 00 00
					// idle_dimming_dbv = 0
					39 00 00 40 00 00 02 6F 04
					39 00 00 00 00 00 03 51 00 00
					// BCTRL = 1, DD = 0
					39 00 00 00 00 00 02 53 20
					// 0x00 Data remap off 0x0F Data remap on
					39 00 00 40 00 00 06 F0 55 AA 52 08 00
					39 00 00 40 00 00 02 6F 02
					39 00 00 40 00 00 02 B2 0F
 					// Skip mode setting
					39 00 00 40 00 00 04 8C 00 00 10
					39 00 00 40 00 00 03 5A 00 00
					39 00 00 00 00 00 02 2F 30
					// AP SPR
					39 00 00 40 00 00 06 F0 55 AA 52 08 03
					39 00 00 40 00 00 02 6F 09
					39 00 00 40 00 00 07 DE 10 34 25 30 14 25
					39 00 00 40 00 00 06 F0 55 AA 52 08 07
					39 00 00 40 00 00 06 B0 84 44 00 00 40
					39 00 00 40 00 00 07 B1 18 08 00 08 18 00
					39 00 00 00 00 00 13 91 AB F0 00 10 C1 00 01 CB 00 73 00 33 06 67 1F B0 11 40
					// Fix 30hz Temp
					39 00 00 40 00 00 06 F0 55 AA 52 08 00
					15 00 00 40 00 00 02 6F 0E
					15 00 00 40 00 00 02 C0 00
					15 00 00 40 00 00 02 6F DE
					15 00 00 40 00 00 02 BA 04
					15 00 00 40 00 00 02 6F 04
					15 00 00 40 00 00 02 35 03
					15 00 00 40 00 00 02 6F 14
					15 00 00 40 00 00 02 35 00
					39 00 00 40 00 00 03 44 0A 60
					15 00 00 40 00 00 02 8C 02
					15 00 00 00 00 00 02 6D 04
					// Still = 0 VDO no RAM
					39 00 00 00 00 00 02 18 00
					// GPO2 = Vsync
					39 00 00 40 00 00 06 F0 55 AA 52 08 00
					39 00 00 40 00 00 02 6F 02
					39 00 00 40 00 00 03 BE 4F 4A
					39 00 00 40 00 00 02 6F 0A
					39 00 00 00 00 00 02 BE 02
					// VDO with RAM
					39 00 00 40 00 00 06 F0 55 AA 52 08 01
					39 00 00 40 00 00 02 6F 17
					39 00 00 00 00 00 02 B8 07
					// GMA By Frame
					39 00 00 40 00 00 06 F0 55 AA 52 08 02
					39 00 00 00 00 00 02 CC 10
					// Idle Mode porch
					39 00 00 40 00 00 05 FF AA 55 A5 81
					39 00 00 40 00 00 02 6F 0F
					39 00 00 00 00 00 02 F5 0E
					// Demura on
					39 00 00 40 00 00 06 F0 55 AA 52 08 04
					39 00 00 00 00 00 02 CA 01
					// A3 Setting
					39 00 00 40 00 00 06 F0 55 AA 52 08 04
					39 00 00 40 00 00 02 6F 06
					39 00 00 40 00 00 02 B5 00
					39 00 00 40 00 00 05 FF AA 55 A5 81
					39 00 00 40 00 00 02 6F 0D
					39 00 00 40 00 00 02 FD 40
					39 00 00 40 00 00 07 51 00 00 00 00 00 00
					39 00 00 00 00 00 06 A3 84 02 5F 02 5F
					// Sleep Out
					05 00 00 00 5F 00 01 11
					// expand demura lut 16DBV*7Gray
					39 00 00 40 00 00 13 A3 84 02 5F 02 5F 02 04 B5 02 03 00 03 00 00 00 00 00 00
					39 00 00 40 00 00 02 6F 12
					39 00 00 40 00 00 0E A3 01 00 9D 00 00 AA 00 00 00 00 00 00 00
					39 00 00 40 00 00 02 6F 53
					39 00 00 40 00 00 0E A3 02 04 B5 02 03 00 0C 00 00 00 00 00 00
					39 00 00 40 00 00 02 6F 60
					39 00 00 00 00 00 0E A3 01 00 9D 00 00 AA 00 00 00 00 00 00 00
					// Display On
					05 00 00 00 00 00 01 29
					// ESD ERR Flag on
					39 00 00 40 00 00 06 F0 55 AA 52 08 00
					15 00 00 40 00 00 02 6F 05
					15 00 00 00 00 00 02 BE 08
					//OD code
					39 00 00 40 00 00 06 F0 55 AA 52 08 08
					15 00 00 40 00 00 02 6F 1B
					39 00 00 40 00 00 07 EB 34 E0 00 05 00 00
					//120Hz DC Skip Frame Rate
					39 00 00 40 00 00 06 F0 55 AA 52 08 00
					15 00 00 40 00 00 02 6F 5A
					39 00 00 00 00 00 09 D1 10 10 00 00 00 01 20 21
				];
				qcom,mdss-dsi-on-command-state = "dsi_lp_mode";
			};
			timing@wqhd_normal_24hz_index_04 {
				#include "dsi-panel-q200-42-02-0a-p21-prim-dsc-cmd-common.dtsi"
				cell-index = <4>;
				qcom,mdss-dsi-panel-framerate = <24>;
				qcom,mdss-dsi-h-sync-skew = <0>;
				qcom,mdss-dsi-timing-switch-command = [
					// Fix 24hz Temp
					39 00 00 40 00 00 06 F0 55 AA 52 08 00
					15 00 00 40 00 00 02 6F 0E
					15 00 00 40 00 00 02 C0 00
					15 00 00 40 00 00 02 6F DE
					15 00 00 40 00 00 02 BA 04
					15 00 00 40 00 00 02 6F 04
					15 00 00 40 00 00 02 35 04
					15 00 00 40 00 00 02 6F 14
					15 00 00 40 00 00 02 35 00
					39 00 00 40 00 00 03 44 0A 60
					15 00 00 40 00 00 02 8C 02
					15 00 00 00 00 00 02 6D 05
				];
				qcom,mdss-dsi-timing-switch-command-state = "dsi_hs_mode";
				mi,mdss-dsi-timing-switch-pwm-command = [
					// Fix 24hz Temp
					39 00 00 40 00 00 06 F0 55 AA 52 08 00
					15 00 00 40 00 00 02 6F 0E
					15 00 00 40 00 00 02 C0 00
					15 00 00 40 00 00 02 6F DE
					15 00 00 40 00 00 02 BA 04
					15 00 00 40 00 00 02 6F 04
					15 00 00 40 00 00 02 35 04
					15 00 00 40 00 00 02 6F 14
					15 00 00 40 00 00 02 35 00
					39 00 00 40 00 00 03 44 0A 60
					15 00 00 40 00 00 02 8C 02
					15 00 00 00 00 00 02 6D 05
				];
				mi,mdss-dsi-timing-switch-pwm-command-state = "dsi_hs_mode";
				qcom,mdss-dsi-on-command = [
					// LCTC ON
					39 00 00 40 00 00 06 F0 55 AA 52 08 08
					15 00 00 40 00 00 02 BF 21
					// ACTC ON
					15 00 00 40 00 00 02 6F B7
					15 00 00 00 00 00 02 BF 11
					// OD ON
					39 00 00 40 00 00 06 F0 55 AA 52 08 08
					15 00 00 00 00 00 02 E0 01
					// VINT power domain
					39 00 00 40 00 00 06 F0 55 AA 52 08 01
					15 00 00 40 00 00 02 6F 49
					39 00 00 00 00 00 06 B9 01 22 00 EE EE
					// AOD pump
					39 00 00 40 00 00 06 F0 55 AA 52 08 01
					39 00 00 00 00 00 05 B2 00 00 FF 03
					// Data chopper setting
					39 00 00 40 00 00 06 F0 55 AA 52 08 01
					15 00 00 40 00 00 02 6F 23
					39 00 00 00 00 00 04 D9 CB 49 13
					// EM TH2 Duty Setting
					39 00 00 40 00 00 06 F0 55 AA 52 08 00
					39 00 00 40 00 00 02 6F 21
					39 00 00 40 00 00 09 B2 00 28 00 28 00 3C 00 28
					39 00 00 40 00 00 02 6F 75
					39 00 00 40 00 00 09 B2 00 28 00 28 00 3C 00 28
					39 00 00 40 00 00 02 6F 71
					39 00 00 00 00 00 03 B2 00 28
					// PMIC Fast discharge
					39 00 00 40 00 00 02 6F 51
					39 00 00 40 00 00 02 D5 02
					39 00 00 40 00 00 02 6F 54
					39 00 00 00 00 00 02 D5 1F
					// Switch VGMP by Fcon
					39 00 00 40 00 00 06 F0 55 AA 52 08 01
					39 00 00 40 00 00 02 6F 16
					39 00 00 00 00 00 05 C6 87 22 2C 2C
					// demura,FLASH CODE
					39 00 00 40 00 00 06 F0 55 AA 52 08 00
					39 00 00 40 00 00 02 C7 44
					39 00 00 40 00 00 02 6F 31
					39 00 00 40 00 00 03 C0 00 20
					39 00 00 40 00 00 02 6F 06
					39 00 00 40 00 00 03 C7 60 60
					39 00 00 40 00 00 02 6F 08
					39 00 00 40 00 00 03 C7 66 26
					39 00 00 40 00 00 06 F0 55 AA 52 08 04
					39 00 00 00 00 00 02 C0 20
					// SVM
					39 00 00 40 00 00 06 F0 55 AA 52 08 00
					39 00 00 40 00 00 02 6F 20
					39 00 00 40 00 00 02 B2 03
					39 00 00 40 00 00 06 F0 55 AA 52 08 01
					39 00 00 40 00 00 02 6F F0
					39 00 00 40 00 00 02 C0 F1
					39 00 00 40 00 00 02 6F F1
					39 00 00 40 00 00 03 C0 12 12
					39 00 00 40 00 00 02 6F F4
					39 00 00 40 00 00 03 C0 12 12
					39 00 00 40 00 00 02 6F 01
					39 00 00 40 00 00 04 CE 00 00 00
					39 00 00 40 00 00 02 6F 94
					39 00 00 40 00 00 04 E2 00 11 00
					39 00 00 40 00 00 02 6F 24
					39 00 00 40 00 00 13 E5 42 8C 94 90 92 07 42 8C 94 90 92 07 42 8C 94 90 92 07
					39 00 00 40 00 00 02 6F A7
					39 00 00 40 00 00 02 E7 C0
					39 00 00 40 00 00 02 6F DA
					39 00 00 40 00 00 03 E7 00 00
					39 00 00 40 00 00 06 F0 55 AA 52 08 01
					39 00 00 40 00 00 02 6F E3
					39 00 00 00 00 00 18 E5 FF FF FF FF 9B 9B 61 61 4D 4D 3A 3A 00 00 00 00 00 00 00 00 00 00 00
					// APL,Normal 32,HBM 8,APL 0
					39 00 00 40 00 00 06 F0 55 AA 52 08 00
					39 00 00 40 00 00 02 6F 78
					39 00 00 40 00 00 18 B0 11 00 2A 00 C2 01 DA 03 7C 05 B1 08 80 0B EE 0F FF 05 55 05 56 05 55
					39 00 00 40 00 00 02 6F 6F
					39 00 00 40 00 00 07 B0 02 62 04 C4 02 62
					39 00 00 40 00 00 06 F0 55 AA 52 08 08
					39 00 00 40 00 00 17 C1 9C FF CC FF FF CC FF FF CC FF FF DC FF FF DD FF FF FF 7F FF 0E FF
					39 00 00 40 00 00 02 6F 1D
					39 00 00 40 00 00 07 C1 00 FF FF 4F 00 FF
					39 00 00 40 00 00 02 6F 23
					39 00 00 40 00 00 15 C1 0C FF CC FF FF CC FF FF CC FF FF DC FF FF DD FF FF CF 7F 67
					39 00 00 40 00 00 02 6F 37
					39 00 00 40 00 00 15 C1 0C FF CC FF FF CC FF FF CC FF FF DC FF FF DD FF FF FF 7F FF
					39 00 00 40 00 00 02 6F 4B
					39 00 00 00 00 00 15 C1 0C FF CC FF FF CC FF FF CC FF FF DC FF FF DD FF FF CF 7F 67
					// Data Scaling DBV_TH
					39 00 00 00 00 00 2D BA 00 07 00 26 00 26 00 64 00 64 00 AC 00 AC 01 26 01 26 02 5F 02 5F 02 60 02 60 07 FB 07 FB 17 FE 17 FE 1F FF 1F FF 34 BC 34 BC 3F FE
					// ESD ERR Flag
					39 00 00 40 00 00 06 F0 55 AA 52 08 00
					39 00 00 40 00 00 03 BE 47 45
					15 00 00 40 00 00 02 6F 05
					15 00 00 40 00 00 02 BE 00
					15 00 00 40 00 00 02 6F 19
					39 00 00 00 00 00 05 BE 10 0A 00 9C
					// DVDD Low Voltage detect
					39 00 00 40 00 00 06 F0 55 AA 52 08 01
					15 00 00 40 00 00 02 6F 03
					15 00 00 00 00 00 02 C7 C7
					// ESD protect
					39 00 00 40 00 00 05 FF AA 55 A5 81
					39 00 00 40 00 00 02 6F 0F
					39 00 00 00 00 00 02 FD 80
					// video trim
					39 00 00 40 00 00 06 F0 55 AA 52 08 01
					39 00 00 40 00 00 37 C3 DD 29 02 6F E3 00 29 00 6F E3 00 3F 49 2E 3F 26 0F 3F 49 2E
											3F 26 0F 3F 49 2E 3F 26 0F 3F 49 2E 3F 26 0F 3F 49 2E 3F 26 0F 11 11 01 11 11 01 77 C0 AA 02 AA 02 00
					39 00 00 00 00 00 24 EA 11 02 3C 00 0D 0B 0A 00 00 00 00 11 02 3C 00 0D 0B 0A 00 00
											00 00 00 00 00 00 00 00 00 00 00 0C 00 00 40
					// 1220*2656
					39 00 00 40 00 00 05 2A 00 00 04 C3
					39 00 00 00 00 00 05 2B 00 00 0A 5F
					// VESA Setting
					39 00 00 40 00 00 02 90 03
					39 00 00 40 00 00 02 6F 01
					39 00 00 40 00 00 02 90 43
					39 00 00 40 00 00 13 91 89 28 00 10 C2 00 02 32 01 9C 00 08 06 67 05 92 10 E0
					// DC 120Hz
					39 00 00 40 00 00 02 2F 30
					39 00 00 00 00 00 02 6D 00
					// TE On
					39 00 00 00 00 00 02 35 00
					// DBV = 0
					39 00 00 00 00 00 03 51 00 00
					// idle_dimming_dbv = 0
					39 00 00 40 00 00 02 6F 04
					39 00 00 00 00 00 03 51 00 00
					// BCTRL = 1, DD = 0
					39 00 00 00 00 00 02 53 20
					// 0x00 Data remap off 0x0F Data remap on
					39 00 00 40 00 00 06 F0 55 AA 52 08 00
					39 00 00 40 00 00 02 6F 02
					39 00 00 40 00 00 02 B2 0F
 					// Skip mode setting
					39 00 00 40 00 00 04 8C 00 00 10
					39 00 00 40 00 00 03 5A 00 00
					39 00 00 00 00 00 02 2F 30
					// AP SPR
					39 00 00 40 00 00 06 F0 55 AA 52 08 03
					39 00 00 40 00 00 02 6F 09
					39 00 00 40 00 00 07 DE 10 34 25 30 14 25
					39 00 00 40 00 00 06 F0 55 AA 52 08 07
					39 00 00 40 00 00 06 B0 84 44 00 00 40
					39 00 00 40 00 00 07 B1 18 08 00 08 18 00
					39 00 00 00 00 00 13 91 AB F0 00 10 C1 00 01 CB 00 73 00 33 06 67 1F B0 11 40
					// Fix 24hz Temp
					39 00 00 40 00 00 06 F0 55 AA 52 08 00
					15 00 00 40 00 00 02 6F 0E
					15 00 00 40 00 00 02 C0 00
					15 00 00 40 00 00 02 6F DE
					15 00 00 40 00 00 02 BA 04
					15 00 00 40 00 00 02 6F 04
					15 00 00 40 00 00 02 35 04
					15 00 00 40 00 00 02 6F 14
					15 00 00 40 00 00 02 35 00
					39 00 00 40 00 00 03 44 0A 60
					15 00 00 40 00 00 02 8C 02
					15 00 00 00 00 00 02 6D 05
					// Still = 0 VDO no RAM
					39 00 00 00 00 00 02 18 00
					// GPO2 = Vsync
					39 00 00 40 00 00 06 F0 55 AA 52 08 00
					39 00 00 40 00 00 02 6F 02
					39 00 00 40 00 00 03 BE 4F 4A
					39 00 00 40 00 00 02 6F 0A
					39 00 00 00 00 00 02 BE 02
					// VDO with RAM
					39 00 00 40 00 00 06 F0 55 AA 52 08 01
					39 00 00 40 00 00 02 6F 17
					39 00 00 00 00 00 02 B8 07
					// GMA By Frame
					39 00 00 40 00 00 06 F0 55 AA 52 08 02
					39 00 00 00 00 00 02 CC 10
					// Idle Mode porch
					39 00 00 40 00 00 05 FF AA 55 A5 81
					39 00 00 40 00 00 02 6F 0F
					39 00 00 00 00 00 02 F5 0E
					// Demura on
					39 00 00 40 00 00 06 F0 55 AA 52 08 04
					39 00 00 00 00 00 02 CA 01
					// A3 Setting
					39 00 00 40 00 00 06 F0 55 AA 52 08 04
					39 00 00 40 00 00 02 6F 06
					39 00 00 40 00 00 02 B5 00
					39 00 00 40 00 00 05 FF AA 55 A5 81
					39 00 00 40 00 00 02 6F 0D
					39 00 00 40 00 00 02 FD 40
					39 00 00 40 00 00 07 51 00 00 00 00 00 00
					39 00 00 00 00 00 06 A3 84 02 5F 02 5F
					// Sleep Out
					05 00 00 00 5F 00 01 11
					// expand demura lut 16DBV*7Gray
					39 00 00 40 00 00 13 A3 84 02 5F 02 5F 02 04 B5 02 03 00 03 00 00 00 00 00 00
					39 00 00 40 00 00 02 6F 12
					39 00 00 40 00 00 0E A3 01 00 9D 00 00 AA 00 00 00 00 00 00 00
					39 00 00 40 00 00 02 6F 53
					39 00 00 40 00 00 0E A3 02 04 B5 02 03 00 0C 00 00 00 00 00 00
					39 00 00 40 00 00 02 6F 60
					39 00 00 00 00 00 0E A3 01 00 9D 00 00 AA 00 00 00 00 00 00 00
					// Display On
					05 00 00 00 00 00 01 29
					// ESD ERR Flag on
					39 00 00 40 00 00 06 F0 55 AA 52 08 00
					15 00 00 40 00 00 02 6F 05
					15 00 00 00 00 00 02 BE 08
					//OD code
					39 00 00 40 00 00 06 F0 55 AA 52 08 08
					15 00 00 40 00 00 02 6F 1B
					39 00 00 40 00 00 07 EB 34 E0 00 05 00 00
					//120Hz DC Skip Frame Rate
					39 00 00 40 00 00 06 F0 55 AA 52 08 00
					15 00 00 40 00 00 02 6F 5A
					39 00 00 00 00 00 09 D1 10 10 00 00 00 01 20 21
				];
				qcom,mdss-dsi-on-command-state = "dsi_lp_mode";
			};
			timing@wqhd_idle_120_to_10hz_index_05 {
				#include "dsi-panel-q200-42-02-0a-p21-prim-dsc-cmd-common.dtsi"
				cell-index = <5>;
				qcom,mdss-dsi-panel-framerate = <120>;
				/* ---------------------------- */
				/* | 15 - 14 | 13 - 7 | 6 - 0 | */
				/* ---------------------------- */
				/* |   mode  | sf fps | min fps| */
				/* ---------------------------- -*/
				/* mode: 1 idle, 2 auto, 3 qsync */
				/*   1 << 14 | 120 << 7 | 10     */
				qcom,mdss-dsi-h-sync-skew = <31754>;
				/* mode: 0 normal, 1 idle, 2 auto, 3 qsync, 4 diff, 5 test */
				mi,mdss-dsi-ddic-mode = "idle";
				mi,mdss-dsi-sf-framerate = <120>;
				mi,mdss-dsi-ddic-min-framerate = <10>;
				qcom,mdss-dsi-timing-switch-command = [
					// 10hz Temp
					39 00 00 40 00 00 06 F0 55 AA 52 08 00
					15 00 00 40 00 00 02 6F 0E
					15 00 00 40 00 00 02 C0 00
					15 00 00 40 00 00 02 6F DE
					15 00 00 40 00 00 02 BA 00
					15 00 00 40 00 00 02 6F 04
					15 00 00 40 00 00 02 35 00
					15 00 00 40 00 00 02 6F 14
					15 00 00 40 00 00 02 35 00
					39 00 00 40 00 00 03 44 0A 60
					15 00 00 40 00 00 02 8C 00
					15 00 00 00 00 00 02 6D 06
				];
				qcom,mdss-dsi-timing-switch-command-state = "dsi_hs_mode";
				mi,mdss-dsi-timing-switch-pwm-command = [
					// 10hz Temp
					39 00 00 40 00 00 06 F0 55 AA 52 08 00
					15 00 00 40 00 00 02 6F 0E
					15 00 00 40 00 00 02 C0 00
					15 00 00 40 00 00 02 6F DE
					15 00 00 40 00 00 02 BA 00
					15 00 00 40 00 00 02 6F 04
					15 00 00 40 00 00 02 35 00
					15 00 00 40 00 00 02 6F 14
					15 00 00 40 00 00 02 35 00
					39 00 00 40 00 00 03 44 0A 60
					15 00 00 40 00 00 02 8C 00
					15 00 00 00 00 00 02 6D 06
				];
				mi,mdss-dsi-timing-switch-pwm-command-state = "dsi_hs_mode";
				qcom,mdss-dsi-on-command = [
					// LCTC ON
					39 00 00 40 00 00 06 F0 55 AA 52 08 08
					15 00 00 40 00 00 02 BF 21
					// ACTC ON
					15 00 00 40 00 00 02 6F B7
					15 00 00 00 00 00 02 BF 11
					// OD ON
					39 00 00 40 00 00 06 F0 55 AA 52 08 08
					15 00 00 00 00 00 02 E0 01
					// VINT power domain
					39 00 00 40 00 00 06 F0 55 AA 52 08 01
					15 00 00 40 00 00 02 6F 49
					39 00 00 00 00 00 06 B9 01 22 00 EE EE
					// AOD pump
					39 00 00 40 00 00 06 F0 55 AA 52 08 01
					39 00 00 00 00 00 05 B2 00 00 FF 03
					// Data chopper setting
					39 00 00 40 00 00 06 F0 55 AA 52 08 01
					15 00 00 40 00 00 02 6F 23
					39 00 00 00 00 00 04 D9 CB 49 13
					// EM TH2 Duty Setting
					39 00 00 40 00 00 06 F0 55 AA 52 08 00
					39 00 00 40 00 00 02 6F 21
					39 00 00 40 00 00 09 B2 00 28 00 28 00 3C 00 28
					39 00 00 40 00 00 02 6F 75
					39 00 00 40 00 00 09 B2 00 28 00 28 00 3C 00 28
					39 00 00 40 00 00 02 6F 71
					39 00 00 00 00 00 03 B2 00 28
					// PMIC Fast discharge
					39 00 00 40 00 00 02 6F 51
					39 00 00 40 00 00 02 D5 02
					39 00 00 40 00 00 02 6F 54
					39 00 00 00 00 00 02 D5 1F
					// Switch VGMP by Fcon
					39 00 00 40 00 00 06 F0 55 AA 52 08 01
					39 00 00 40 00 00 02 6F 16
					39 00 00 00 00 00 05 C6 87 22 2C 2C
					// demura,FLASH CODE
					39 00 00 40 00 00 06 F0 55 AA 52 08 00
					39 00 00 40 00 00 02 C7 44
					39 00 00 40 00 00 02 6F 31
					39 00 00 40 00 00 03 C0 00 20
					39 00 00 40 00 00 02 6F 06
					39 00 00 40 00 00 03 C7 60 60
					39 00 00 40 00 00 02 6F 08
					39 00 00 40 00 00 03 C7 66 26
					39 00 00 40 00 00 06 F0 55 AA 52 08 04
					39 00 00 00 00 00 02 C0 20
					// SVM
					39 00 00 40 00 00 06 F0 55 AA 52 08 00
					39 00 00 40 00 00 02 6F 20
					39 00 00 40 00 00 02 B2 03
					39 00 00 40 00 00 06 F0 55 AA 52 08 01
					39 00 00 40 00 00 02 6F F0
					39 00 00 40 00 00 02 C0 F1
					39 00 00 40 00 00 02 6F F1
					39 00 00 40 00 00 03 C0 12 12
					39 00 00 40 00 00 02 6F F4
					39 00 00 40 00 00 03 C0 12 12
					39 00 00 40 00 00 02 6F 01
					39 00 00 40 00 00 04 CE 00 00 00
					39 00 00 40 00 00 02 6F 94
					39 00 00 40 00 00 04 E2 00 11 00
					39 00 00 40 00 00 02 6F 24
					39 00 00 40 00 00 13 E5 42 8C 94 90 92 07 42 8C 94 90 92 07 42 8C 94 90 92 07
					39 00 00 40 00 00 02 6F A7
					39 00 00 40 00 00 02 E7 C0
					39 00 00 40 00 00 02 6F DA
					39 00 00 40 00 00 03 E7 00 00
					39 00 00 40 00 00 06 F0 55 AA 52 08 01
					39 00 00 40 00 00 02 6F E3
					39 00 00 00 00 00 18 E5 FF FF FF FF 9B 9B 61 61 4D 4D 3A 3A 00 00 00 00 00 00 00 00 00 00 00
					// APL,Normal 32,HBM 8,APL 0
					39 00 00 40 00 00 06 F0 55 AA 52 08 00
					39 00 00 40 00 00 02 6F 78
					39 00 00 40 00 00 18 B0 11 00 2A 00 C2 01 DA 03 7C 05 B1 08 80 0B EE 0F FF 05 55 05 56 05 55
					39 00 00 40 00 00 02 6F 6F
					39 00 00 40 00 00 07 B0 02 62 04 C4 02 62
					39 00 00 40 00 00 06 F0 55 AA 52 08 08
					39 00 00 40 00 00 17 C1 9C FF CC FF FF CC FF FF CC FF FF DC FF FF DD FF FF FF 7F FF 0E FF
					39 00 00 40 00 00 02 6F 1D
					39 00 00 40 00 00 07 C1 00 FF FF 4F 00 FF
					39 00 00 40 00 00 02 6F 23
					39 00 00 40 00 00 15 C1 0C FF CC FF FF CC FF FF CC FF FF DC FF FF DD FF FF CF 7F 67
					39 00 00 40 00 00 02 6F 37
					39 00 00 40 00 00 15 C1 0C FF CC FF FF CC FF FF CC FF FF DC FF FF DD FF FF FF 7F FF
					39 00 00 40 00 00 02 6F 4B
					39 00 00 00 00 00 15 C1 0C FF CC FF FF CC FF FF CC FF FF DC FF FF DD FF FF CF 7F 67
					// Data Scaling DBV_TH
					39 00 00 00 00 00 2D BA 00 07 00 26 00 26 00 64 00 64 00 AC 00 AC 01 26 01 26 02 5F 02 5F 02 60 02 60 07 FB 07 FB 17 FE 17 FE 1F FF 1F FF 34 BC 34 BC 3F FE
					// ESD ERR Flag
					39 00 00 40 00 00 06 F0 55 AA 52 08 00
					39 00 00 40 00 00 03 BE 47 45
					15 00 00 40 00 00 02 6F 05
					15 00 00 40 00 00 02 BE 00
					15 00 00 40 00 00 02 6F 19
					39 00 00 00 00 00 05 BE 10 0A 00 9C
					// DVDD Low Voltage detect
					39 00 00 40 00 00 06 F0 55 AA 52 08 01
					15 00 00 40 00 00 02 6F 03
					15 00 00 00 00 00 02 C7 C7
					// ESD protect
					39 00 00 40 00 00 05 FF AA 55 A5 81
					39 00 00 40 00 00 02 6F 0F
					39 00 00 00 00 00 02 FD 80
					// video trim
					39 00 00 40 00 00 06 F0 55 AA 52 08 01
					39 00 00 40 00 00 37 C3 DD 29 02 6F E3 00 29 00 6F E3 00 3F 49 2E 3F 26 0F 3F 49 2E
											3F 26 0F 3F 49 2E 3F 26 0F 3F 49 2E 3F 26 0F 3F 49 2E 3F 26 0F 11 11 01 11 11 01 77 C0 AA 02 AA 02 00
					39 00 00 00 00 00 24 EA 11 02 3C 00 0D 0B 0A 00 00 00 00 11 02 3C 00 0D 0B 0A 00 00
											00 00 00 00 00 00 00 00 00 00 00 0C 00 00 40
					// 1220*2656
					39 00 00 40 00 00 05 2A 00 00 04 C3
					39 00 00 00 00 00 05 2B 00 00 0A 5F
					// VESA Setting
					39 00 00 40 00 00 02 90 03
					39 00 00 40 00 00 02 6F 01
					39 00 00 40 00 00 02 90 43
					39 00 00 40 00 00 13 91 89 28 00 10 C2 00 02 32 01 9C 00 08 06 67 05 92 10 E0
					// DC 120Hz
					39 00 00 40 00 00 02 2F 30
					39 00 00 00 00 00 02 6D 00
					// TE On
					39 00 00 00 00 00 02 35 00
					// DBV = 0
					39 00 00 00 00 00 03 51 00 00
					// idle_dimming_dbv = 0
					39 00 00 40 00 00 02 6F 04
					39 00 00 00 00 00 03 51 00 00
					// BCTRL = 1, DD = 0
					39 00 00 00 00 00 02 53 20
					// 0x00 Data remap off 0x0F Data remap on
					39 00 00 40 00 00 06 F0 55 AA 52 08 00
					39 00 00 40 00 00 02 6F 02
					39 00 00 40 00 00 02 B2 0F
 					// Skip mode setting
					39 00 00 40 00 00 04 8C 00 00 10
					39 00 00 40 00 00 03 5A 00 00
					39 00 00 00 00 00 02 2F 30
					// AP SPR
					39 00 00 40 00 00 06 F0 55 AA 52 08 03
					39 00 00 40 00 00 02 6F 09
					39 00 00 40 00 00 07 DE 10 34 25 30 14 25
					39 00 00 40 00 00 06 F0 55 AA 52 08 07
					39 00 00 40 00 00 06 B0 84 44 00 00 40
					39 00 00 40 00 00 07 B1 18 08 00 08 18 00
					39 00 00 00 00 00 13 91 AB F0 00 10 C1 00 01 CB 00 73 00 33 06 67 1F B0 11 40
					// 10hz Temp
					39 00 00 40 00 00 06 F0 55 AA 52 08 00
					15 00 00 40 00 00 02 6F 0E
					15 00 00 40 00 00 02 C0 00
					15 00 00 40 00 00 02 6F DE
					15 00 00 40 00 00 02 BA 00
					15 00 00 40 00 00 02 6F 04
					15 00 00 40 00 00 02 35 00
					15 00 00 40 00 00 02 6F 14
					15 00 00 40 00 00 02 35 00
					39 00 00 40 00 00 03 44 0A 60
					15 00 00 40 00 00 02 8C 00
					15 00 00 00 00 00 02 6D 06
					// Still = 0 VDO no RAM
					39 00 00 00 00 00 02 18 00
					// GPO2 = Vsync
					39 00 00 40 00 00 06 F0 55 AA 52 08 00
					39 00 00 40 00 00 02 6F 02
					39 00 00 40 00 00 03 BE 4F 4A
					39 00 00 40 00 00 02 6F 0A
					39 00 00 00 00 00 02 BE 02
					// VDO with RAM
					39 00 00 40 00 00 06 F0 55 AA 52 08 01
					39 00 00 40 00 00 02 6F 17
					39 00 00 00 00 00 02 B8 07
					// GMA By Frame
					39 00 00 40 00 00 06 F0 55 AA 52 08 02
					39 00 00 00 00 00 02 CC 10
					// Idle Mode porch
					39 00 00 40 00 00 05 FF AA 55 A5 81
					39 00 00 40 00 00 02 6F 0F
					39 00 00 00 00 00 02 F5 0E
					// Demura on
					39 00 00 40 00 00 06 F0 55 AA 52 08 04
					39 00 00 00 00 00 02 CA 01
					// A3 Setting
					39 00 00 40 00 00 06 F0 55 AA 52 08 04
					39 00 00 40 00 00 02 6F 06
					39 00 00 40 00 00 02 B5 00
					39 00 00 40 00 00 05 FF AA 55 A5 81
					39 00 00 40 00 00 02 6F 0D
					39 00 00 40 00 00 02 FD 40
					39 00 00 40 00 00 07 51 00 00 00 00 00 00
					39 00 00 00 00 00 06 A3 84 02 5F 02 5F
					// Sleep Out
					05 00 00 00 5F 00 01 11
					// expand demura lut 16DBV*7Gray
					39 00 00 40 00 00 13 A3 84 02 5F 02 5F 02 04 B5 02 03 00 03 00 00 00 00 00 00
					39 00 00 40 00 00 02 6F 12
					39 00 00 40 00 00 0E A3 01 00 9D 00 00 AA 00 00 00 00 00 00 00
					39 00 00 40 00 00 02 6F 53
					39 00 00 40 00 00 0E A3 02 04 B5 02 03 00 0C 00 00 00 00 00 00
					39 00 00 40 00 00 02 6F 60
					39 00 00 00 00 00 0E A3 01 00 9D 00 00 AA 00 00 00 00 00 00 00
					// Display On
					05 00 00 00 00 00 01 29
					// ESD ERR Flag on
					39 00 00 40 00 00 06 F0 55 AA 52 08 00
					15 00 00 40 00 00 02 6F 05
					15 00 00 00 00 00 02 BE 08
					//OD code
					39 00 00 40 00 00 06 F0 55 AA 52 08 08
					15 00 00 40 00 00 02 6F 1B
					39 00 00 40 00 00 07 EB 34 E0 00 05 00 00
					//120Hz DC Skip Frame Rate
					39 00 00 40 00 00 06 F0 55 AA 52 08 00
					15 00 00 40 00 00 02 6F 5A
					39 00 00 00 00 00 09 D1 10 10 00 00 00 01 20 21
				];
				qcom,mdss-dsi-on-command-state = "dsi_lp_mode";
			};
			timing@wqhd_idle_120_to_1hz_index_06 {
				#include "dsi-panel-q200-42-02-0a-p21-prim-dsc-cmd-common.dtsi"
				cell-index = <6>;
				qcom,mdss-dsi-panel-framerate = <120>;
				/* ---------------------------- */
				/* | 15 - 14 | 13 - 7 | 6 - 0 | */
				/* ---------------------------- */
				/* |   mode  | sf fps | min fps| */
				/* ---------------------------- -*/
				/* mode: 1 idle, 2 auto, 3 qsync */
				/*   1 << 14 | 120 << 7 | 10     */
				qcom,mdss-dsi-h-sync-skew = <31745>;
				/* mode: 0 normal, 1 idle, 2 auto, 3 qsync, 4 diff, 5 test */
				mi,mdss-dsi-ddic-mode = "idle";
				mi,mdss-dsi-sf-framerate = <120>;
				mi,mdss-dsi-ddic-min-framerate = <1>;
				qcom,mdss-dsi-timing-switch-command = [
					// 1hz Temp
					39 00 00 40 00 00 06 F0 55 AA 52 08 00
					15 00 00 40 00 00 02 6F 0E
					15 00 00 40 00 00 02 C0 00
					15 00 00 40 00 00 02 6F DE
					15 00 00 40 00 00 02 BA 00
					15 00 00 40 00 00 02 6F 04
					15 00 00 40 00 00 02 35 00
					15 00 00 40 00 00 02 6F 14
					15 00 00 40 00 00 02 35 00
					39 00 00 40 00 00 03 44 0A 60
					15 00 00 40 00 00 02 8C 00
					15 00 00 00 00 00 02 6D 09
				];
				qcom,mdss-dsi-timing-switch-command-state = "dsi_hs_mode";
				mi,mdss-dsi-timing-switch-pwm-command = [
					// 1hz Temp
					39 00 00 40 00 00 06 F0 55 AA 52 08 00
					15 00 00 40 00 00 02 6F 0E
					15 00 00 40 00 00 02 C0 00
					15 00 00 40 00 00 02 6F DE
					15 00 00 40 00 00 02 BA 00
					15 00 00 40 00 00 02 6F 04
					15 00 00 40 00 00 02 35 00
					15 00 00 40 00 00 02 6F 14
					15 00 00 40 00 00 02 35 00
					39 00 00 40 00 00 03 44 0A 60
					15 00 00 40 00 00 02 8C 00
					15 00 00 00 00 00 02 6D 09
				];
				mi,mdss-dsi-timing-switch-pwm-command-state = "dsi_hs_mode";
				qcom,mdss-dsi-on-command = [
					// LCTC ON
					39 00 00 40 00 00 06 F0 55 AA 52 08 08
					15 00 00 40 00 00 02 BF 21
					// ACTC ON
					15 00 00 40 00 00 02 6F B7
					15 00 00 00 00 00 02 BF 11
					// OD ON
					39 00 00 40 00 00 06 F0 55 AA 52 08 08
					15 00 00 00 00 00 02 E0 01
					// VINT power domain
					39 00 00 40 00 00 06 F0 55 AA 52 08 01
					15 00 00 40 00 00 02 6F 49
					39 00 00 00 00 00 06 B9 01 22 00 EE EE
					// AOD pump
					39 00 00 40 00 00 06 F0 55 AA 52 08 01
					39 00 00 00 00 00 05 B2 00 00 FF 03
					// Data chopper setting
					39 00 00 40 00 00 06 F0 55 AA 52 08 01
					15 00 00 40 00 00 02 6F 23
					39 00 00 00 00 00 04 D9 CB 49 13
					// EM TH2 Duty Setting
					39 00 00 40 00 00 06 F0 55 AA 52 08 00
					39 00 00 40 00 00 02 6F 21
					39 00 00 40 00 00 09 B2 00 28 00 28 00 3C 00 28
					39 00 00 40 00 00 02 6F 75
					39 00 00 40 00 00 09 B2 00 28 00 28 00 3C 00 28
					39 00 00 40 00 00 02 6F 71
					39 00 00 00 00 00 03 B2 00 28
					// PMIC Fast discharge
					39 00 00 40 00 00 02 6F 51
					39 00 00 40 00 00 02 D5 02
					39 00 00 40 00 00 02 6F 54
					39 00 00 00 00 00 02 D5 1F
					// Switch VGMP by Fcon
					39 00 00 40 00 00 06 F0 55 AA 52 08 01
					39 00 00 40 00 00 02 6F 16
					39 00 00 00 00 00 05 C6 87 22 2C 2C
					// demura,FLASH CODE
					39 00 00 40 00 00 06 F0 55 AA 52 08 00
					39 00 00 40 00 00 02 C7 44
					39 00 00 40 00 00 02 6F 31
					39 00 00 40 00 00 03 C0 00 20
					39 00 00 40 00 00 02 6F 06
					39 00 00 40 00 00 03 C7 60 60
					39 00 00 40 00 00 02 6F 08
					39 00 00 40 00 00 03 C7 66 26
					39 00 00 40 00 00 06 F0 55 AA 52 08 04
					39 00 00 00 00 00 02 C0 20
					// SVM
					39 00 00 40 00 00 06 F0 55 AA 52 08 00
					39 00 00 40 00 00 02 6F 20
					39 00 00 40 00 00 02 B2 03
					39 00 00 40 00 00 06 F0 55 AA 52 08 01
					39 00 00 40 00 00 02 6F F0
					39 00 00 40 00 00 02 C0 F1
					39 00 00 40 00 00 02 6F F1
					39 00 00 40 00 00 03 C0 12 12
					39 00 00 40 00 00 02 6F F4
					39 00 00 40 00 00 03 C0 12 12
					39 00 00 40 00 00 02 6F 01
					39 00 00 40 00 00 04 CE 00 00 00
					39 00 00 40 00 00 02 6F 94
					39 00 00 40 00 00 04 E2 00 11 00
					39 00 00 40 00 00 02 6F 24
					39 00 00 40 00 00 13 E5 42 8C 94 90 92 07 42 8C 94 90 92 07 42 8C 94 90 92 07
					39 00 00 40 00 00 02 6F A7
					39 00 00 40 00 00 02 E7 C0
					39 00 00 40 00 00 02 6F DA
					39 00 00 40 00 00 03 E7 00 00
					39 00 00 40 00 00 06 F0 55 AA 52 08 01
					39 00 00 40 00 00 02 6F E3
					39 00 00 00 00 00 18 E5 FF FF FF FF 9B 9B 61 61 4D 4D 3A 3A 00 00 00 00 00 00 00 00 00 00 00
					// APL,Normal 32,HBM 8,APL 0
					39 00 00 40 00 00 06 F0 55 AA 52 08 00
					39 00 00 40 00 00 02 6F 78
					39 00 00 40 00 00 18 B0 11 00 2A 00 C2 01 DA 03 7C 05 B1 08 80 0B EE 0F FF 05 55 05 56 05 55
					39 00 00 40 00 00 02 6F 6F
					39 00 00 40 00 00 07 B0 02 62 04 C4 02 62
					39 00 00 40 00 00 06 F0 55 AA 52 08 08
					39 00 00 40 00 00 17 C1 9C FF CC FF FF CC FF FF CC FF FF DC FF FF DD FF FF FF 7F FF 0E FF
					39 00 00 40 00 00 02 6F 1D
					39 00 00 40 00 00 07 C1 00 FF FF 4F 00 FF
					39 00 00 40 00 00 02 6F 23
					39 00 00 40 00 00 15 C1 0C FF CC FF FF CC FF FF CC FF FF DC FF FF DD FF FF CF 7F 67
					39 00 00 40 00 00 02 6F 37
					39 00 00 40 00 00 15 C1 0C FF CC FF FF CC FF FF CC FF FF DC FF FF DD FF FF FF 7F FF
					39 00 00 40 00 00 02 6F 4B
					39 00 00 00 00 00 15 C1 0C FF CC FF FF CC FF FF CC FF FF DC FF FF DD FF FF CF 7F 67
					// Data Scaling DBV_TH
					39 00 00 00 00 00 2D BA 00 07 00 26 00 26 00 64 00 64 00 AC 00 AC 01 26 01 26 02 5F 02 5F 02 60 02 60 07 FB 07 FB 17 FE 17 FE 1F FF 1F FF 34 BC 34 BC 3F FE
					// ESD ERR Flag
					39 00 00 40 00 00 06 F0 55 AA 52 08 00
					39 00 00 40 00 00 03 BE 47 45
					15 00 00 40 00 00 02 6F 05
					15 00 00 40 00 00 02 BE 00
					15 00 00 40 00 00 02 6F 19
					39 00 00 00 00 00 05 BE 10 0A 00 9C
					// DVDD Low Voltage detect
					39 00 00 40 00 00 06 F0 55 AA 52 08 01
					15 00 00 40 00 00 02 6F 03
					15 00 00 00 00 00 02 C7 C7
					// ESD protect
					39 00 00 40 00 00 05 FF AA 55 A5 81
					39 00 00 40 00 00 02 6F 0F
					39 00 00 00 00 00 02 FD 80
					// video trim
					39 00 00 40 00 00 06 F0 55 AA 52 08 01
					39 00 00 40 00 00 37 C3 DD 29 02 6F E3 00 29 00 6F E3 00 3F 49 2E 3F 26 0F 3F 49 2E
											3F 26 0F 3F 49 2E 3F 26 0F 3F 49 2E 3F 26 0F 3F 49 2E 3F 26 0F 11 11 01 11 11 01 77 C0 AA 02 AA 02 00
					39 00 00 00 00 00 24 EA 11 02 3C 00 0D 0B 0A 00 00 00 00 11 02 3C 00 0D 0B 0A 00 00
											00 00 00 00 00 00 00 00 00 00 00 0C 00 00 40
					// 1220*2656
					39 00 00 40 00 00 05 2A 00 00 04 C3
					39 00 00 00 00 00 05 2B 00 00 0A 5F
					// VESA Setting
					39 00 00 40 00 00 02 90 03
					39 00 00 40 00 00 02 6F 01
					39 00 00 40 00 00 02 90 43
					39 00 00 40 00 00 13 91 89 28 00 10 C2 00 02 32 01 9C 00 08 06 67 05 92 10 E0
					// DC 120Hz
					39 00 00 40 00 00 02 2F 30
					39 00 00 00 00 00 02 6D 00
					// TE On
					39 00 00 00 00 00 02 35 00
					// DBV = 0
					39 00 00 00 00 00 03 51 00 00
					// idle_dimming_dbv = 0
					39 00 00 40 00 00 02 6F 04
					39 00 00 00 00 00 03 51 00 00
					// BCTRL = 1, DD = 0
					39 00 00 00 00 00 02 53 20
					// 0x00 Data remap off 0x0F Data remap on
					39 00 00 40 00 00 06 F0 55 AA 52 08 00
					39 00 00 40 00 00 02 6F 02
					39 00 00 40 00 00 02 B2 0F
 					// Skip mode setting
					39 00 00 40 00 00 04 8C 00 00 10
					39 00 00 40 00 00 03 5A 00 00
					39 00 00 00 00 00 02 2F 30
					// AP SPR
					39 00 00 40 00 00 06 F0 55 AA 52 08 03
					39 00 00 40 00 00 02 6F 09
					39 00 00 40 00 00 07 DE 10 34 25 30 14 25
					39 00 00 40 00 00 06 F0 55 AA 52 08 07
					39 00 00 40 00 00 06 B0 84 44 00 00 40
					39 00 00 40 00 00 07 B1 18 08 00 08 18 00
					39 00 00 00 00 00 13 91 AB F0 00 10 C1 00 01 CB 00 73 00 33 06 67 1F B0 11 40
					// 1hz Temp
					39 00 00 40 00 00 06 F0 55 AA 52 08 00
					15 00 00 40 00 00 02 6F 0E
					15 00 00 40 00 00 02 C0 00
					15 00 00 40 00 00 02 6F DE
					15 00 00 40 00 00 02 BA 00
					15 00 00 40 00 00 02 6F 04
					15 00 00 40 00 00 02 35 00
					15 00 00 40 00 00 02 6F 14
					15 00 00 40 00 00 02 35 00
					39 00 00 40 00 00 03 44 0A 60
					15 00 00 40 00 00 02 8C 00
					15 00 00 00 00 00 02 6D 09
					// Still = 0 VDO no RAM
					39 00 00 00 00 00 02 18 00
					// GPO2 = Vsync
					39 00 00 40 00 00 06 F0 55 AA 52 08 00
					39 00 00 40 00 00 02 6F 02
					39 00 00 40 00 00 03 BE 4F 4A
					39 00 00 40 00 00 02 6F 0A
					39 00 00 00 00 00 02 BE 02
					// VDO with RAM
					39 00 00 40 00 00 06 F0 55 AA 52 08 01
					39 00 00 40 00 00 02 6F 17
					39 00 00 00 00 00 02 B8 07
					// GMA By Frame
					39 00 00 40 00 00 06 F0 55 AA 52 08 02
					39 00 00 00 00 00 02 CC 10
					// Idle Mode porch
					39 00 00 40 00 00 05 FF AA 55 A5 81
					39 00 00 40 00 00 02 6F 0F
					39 00 00 00 00 00 02 F5 0E
					// Demura on
					39 00 00 40 00 00 06 F0 55 AA 52 08 04
					39 00 00 00 00 00 02 CA 01
					// A3 Setting
					39 00 00 40 00 00 06 F0 55 AA 52 08 04
					39 00 00 40 00 00 02 6F 06
					39 00 00 40 00 00 02 B5 00
					39 00 00 40 00 00 05 FF AA 55 A5 81
					39 00 00 40 00 00 02 6F 0D
					39 00 00 40 00 00 02 FD 40
					39 00 00 40 00 00 07 51 00 00 00 00 00 00
					39 00 00 00 00 00 06 A3 84 02 5F 02 5F
					// Sleep Out
					05 00 00 00 5F 00 01 11
					// expand demura lut 16DBV*7Gray
					39 00 00 40 00 00 13 A3 84 02 5F 02 5F 02 04 B5 02 03 00 03 00 00 00 00 00 00
					39 00 00 40 00 00 02 6F 12
					39 00 00 40 00 00 0E A3 01 00 9D 00 00 AA 00 00 00 00 00 00 00
					39 00 00 40 00 00 02 6F 53
					39 00 00 40 00 00 0E A3 02 04 B5 02 03 00 0C 00 00 00 00 00 00
					39 00 00 40 00 00 02 6F 60
					39 00 00 00 00 00 0E A3 01 00 9D 00 00 AA 00 00 00 00 00 00 00
					// Display On
					05 00 00 00 00 00 01 29
					// ESD ERR Flag on
					39 00 00 40 00 00 06 F0 55 AA 52 08 00
					15 00 00 40 00 00 02 6F 05
					15 00 00 00 00 00 02 BE 08
					//OD code
					39 00 00 40 00 00 06 F0 55 AA 52 08 08
					15 00 00 40 00 00 02 6F 1B
					39 00 00 40 00 00 07 EB 34 E0 00 05 00 00
					//120Hz DC Skip Frame Rate
					39 00 00 40 00 00 06 F0 55 AA 52 08 00
					15 00 00 40 00 00 02 6F 5A
					39 00 00 00 00 00 09 D1 10 10 00 00 00 01 20 21
				];
				qcom,mdss-dsi-on-command-state = "dsi_lp_mode";
			};
			timing@wqhd_auto_60_to_1hz_index_7 {
				#include "dsi-panel-q200-42-02-0a-p21-prim-dsc-cmd-common.dtsi"
				cell-index = <7>;
				qcom,mdss-dsi-panel-framerate = <60>;
				/* ---------------------------- */
				/* | 15 - 14 | 13 - 7 | 6 - 0 | */
				/* ---------------------------- */
				/* |   mode  | sf fps | min fps| */
				/* ---------------------------- -*/
				/* mode: 1 idle, 2 auto, 3 qsync */
				/*   2 << 14 | 60 << 7 | 10     */
				qcom,mdss-dsi-h-sync-skew = <40449>;
				/* mode: 0 normal, 1 idle, 2 auto, 3 qsync, 4 diff, 5 test */
				mi,mdss-dsi-ddic-mode = "auto";
				mi,mdss-dsi-sf-framerate = <60>;
				mi,mdss-dsi-ddic-min-framerate = <1>;
				qcom,mdss-dsi-timing-switch-command = [
					// AUTO 60hz Temp
					39 00 00 40 00 00 06 F0 55 AA 52 08 00
					15 00 00 40 00 00 02 6F 0E
					15 00 00 40 00 00 02 C0 00
					15 00 00 40 00 00 02 6F DE
					15 00 00 40 00 00 02 BA 00
					15 00 00 40 00 00 02 6F 04
					15 00 00 40 00 00 02 35 01
					15 00 00 40 00 00 02 6F 14
					15 00 00 40 00 00 02 35 00
					39 00 00 40 00 00 03 44 0A 60
					15 00 00 40 00 00 02 8C 00
					15 00 00 00 00 00 02 6D 0B
				];
				qcom,mdss-dsi-timing-switch-command-state = "dsi_hs_mode";
				mi,mdss-dsi-timing-switch-pwm-command = [
					// AUTO 60hz Temp
					39 00 00 40 00 00 06 F0 55 AA 52 08 00
					15 00 00 40 00 00 02 6F 0E
					15 00 00 40 00 00 02 C0 00
					15 00 00 40 00 00 02 6F DE
					15 00 00 40 00 00 02 BA 00
					15 00 00 40 00 00 02 6F 04
					15 00 00 40 00 00 02 35 01
					15 00 00 40 00 00 02 6F 14
					15 00 00 40 00 00 02 35 00
					39 00 00 40 00 00 03 44 0A 60
					15 00 00 40 00 00 02 8C 00
					15 00 00 00 00 00 02 6D 0B
				];
				mi,mdss-dsi-timing-switch-pwm-command-state = "dsi_hs_mode";
				qcom,mdss-dsi-on-command = [
					// LCTC ON
					39 00 00 40 00 00 06 F0 55 AA 52 08 08
					15 00 00 40 00 00 02 BF 21
					// ACTC ON
					15 00 00 40 00 00 02 6F B7
					15 00 00 00 00 00 02 BF 11
					// OD ON
					39 00 00 40 00 00 06 F0 55 AA 52 08 08
					15 00 00 00 00 00 02 E0 01
					// VINT power domain
					39 00 00 40 00 00 06 F0 55 AA 52 08 01
					15 00 00 40 00 00 02 6F 49
					39 00 00 00 00 00 06 B9 01 22 00 EE EE
					// AOD pump
					39 00 00 40 00 00 06 F0 55 AA 52 08 01
					39 00 00 00 00 00 05 B2 00 00 FF 03
					// Data chopper setting
					39 00 00 40 00 00 06 F0 55 AA 52 08 01
					15 00 00 40 00 00 02 6F 23
					39 00 00 00 00 00 04 D9 CB 49 13
					// EM TH2 Duty Setting
					39 00 00 40 00 00 06 F0 55 AA 52 08 00
					39 00 00 40 00 00 02 6F 21
					39 00 00 40 00 00 09 B2 00 28 00 28 00 3C 00 28
					39 00 00 40 00 00 02 6F 75
					39 00 00 40 00 00 09 B2 00 28 00 28 00 3C 00 28
					39 00 00 40 00 00 02 6F 71
					39 00 00 00 00 00 03 B2 00 28
					// PMIC Fast discharge
					39 00 00 40 00 00 02 6F 51
					39 00 00 40 00 00 02 D5 02
					39 00 00 40 00 00 02 6F 54
					39 00 00 00 00 00 02 D5 1F
					// Switch VGMP by Fcon
					39 00 00 40 00 00 06 F0 55 AA 52 08 01
					39 00 00 40 00 00 02 6F 16
					39 00 00 00 00 00 05 C6 87 22 2C 2C
					// demura,FLASH CODE
					39 00 00 40 00 00 06 F0 55 AA 52 08 00
					39 00 00 40 00 00 02 C7 44
					39 00 00 40 00 00 02 6F 31
					39 00 00 40 00 00 03 C0 00 20
					39 00 00 40 00 00 02 6F 06
					39 00 00 40 00 00 03 C7 60 60
					39 00 00 40 00 00 02 6F 08
					39 00 00 40 00 00 03 C7 66 26
					39 00 00 40 00 00 06 F0 55 AA 52 08 04
					39 00 00 00 00 00 02 C0 20
					// SVM
					39 00 00 40 00 00 06 F0 55 AA 52 08 00
					39 00 00 40 00 00 02 6F 20
					39 00 00 40 00 00 02 B2 03
					39 00 00 40 00 00 06 F0 55 AA 52 08 01
					39 00 00 40 00 00 02 6F F0
					39 00 00 40 00 00 02 C0 F1
					39 00 00 40 00 00 02 6F F1
					39 00 00 40 00 00 03 C0 12 12
					39 00 00 40 00 00 02 6F F4
					39 00 00 40 00 00 03 C0 12 12
					39 00 00 40 00 00 02 6F 01
					39 00 00 40 00 00 04 CE 00 00 00
					39 00 00 40 00 00 02 6F 94
					39 00 00 40 00 00 04 E2 00 11 00
					39 00 00 40 00 00 02 6F 24
					39 00 00 40 00 00 13 E5 42 8C 94 90 92 07 42 8C 94 90 92 07 42 8C 94 90 92 07
					39 00 00 40 00 00 02 6F A7
					39 00 00 40 00 00 02 E7 C0
					39 00 00 40 00 00 02 6F DA
					39 00 00 40 00 00 03 E7 00 00
					39 00 00 40 00 00 06 F0 55 AA 52 08 01
					39 00 00 40 00 00 02 6F E3
					39 00 00 00 00 00 18 E5 FF FF FF FF 9B 9B 61 61 4D 4D 3A 3A 00 00 00 00 00 00 00 00 00 00 00
					// APL,Normal 32,HBM 8,APL 0
					39 00 00 40 00 00 06 F0 55 AA 52 08 00
					39 00 00 40 00 00 02 6F 78
					39 00 00 40 00 00 18 B0 11 00 2A 00 C2 01 DA 03 7C 05 B1 08 80 0B EE 0F FF 05 55 05 56 05 55
					39 00 00 40 00 00 02 6F 6F
					39 00 00 40 00 00 07 B0 02 62 04 C4 02 62
					39 00 00 40 00 00 06 F0 55 AA 52 08 08
					39 00 00 40 00 00 17 C1 9C FF CC FF FF CC FF FF CC FF FF DC FF FF DD FF FF FF 7F FF 0E FF
					39 00 00 40 00 00 02 6F 1D
					39 00 00 40 00 00 07 C1 00 FF FF 4F 00 FF
					39 00 00 40 00 00 02 6F 23
					39 00 00 40 00 00 15 C1 0C FF CC FF FF CC FF FF CC FF FF DC FF FF DD FF FF CF 7F 67
					39 00 00 40 00 00 02 6F 37
					39 00 00 40 00 00 15 C1 0C FF CC FF FF CC FF FF CC FF FF DC FF FF DD FF FF FF 7F FF
					39 00 00 40 00 00 02 6F 4B
					39 00 00 00 00 00 15 C1 0C FF CC FF FF CC FF FF CC FF FF DC FF FF DD FF FF CF 7F 67
					// Data Scaling DBV_TH
					39 00 00 00 00 00 2D BA 00 07 00 26 00 26 00 64 00 64 00 AC 00 AC 01 26 01 26 02 5F 02 5F 02 60 02 60 07 FB 07 FB 17 FE 17 FE 1F FF 1F FF 34 BC 34 BC 3F FE
					// ESD ERR Flag
					39 00 00 40 00 00 06 F0 55 AA 52 08 00
					39 00 00 40 00 00 03 BE 47 45
					15 00 00 40 00 00 02 6F 05
					15 00 00 40 00 00 02 BE 00
					15 00 00 40 00 00 02 6F 19
					39 00 00 00 00 00 05 BE 10 0A 00 9C
					// DVDD Low Voltage detect
					39 00 00 40 00 00 06 F0 55 AA 52 08 01
					15 00 00 40 00 00 02 6F 03
					15 00 00 00 00 00 02 C7 C7
					// ESD protect
					39 00 00 40 00 00 05 FF AA 55 A5 81
					39 00 00 40 00 00 02 6F 0F
					39 00 00 00 00 00 02 FD 80
					// video trim
					39 00 00 40 00 00 06 F0 55 AA 52 08 01
					39 00 00 40 00 00 37 C3 DD 29 02 6F E3 00 29 00 6F E3 00 3F 49 2E 3F 26 0F 3F 49 2E
											3F 26 0F 3F 49 2E 3F 26 0F 3F 49 2E 3F 26 0F 3F 49 2E 3F 26 0F 11 11 01 11 11 01 77 C0 AA 02 AA 02 00
					39 00 00 00 00 00 24 EA 11 02 3C 00 0D 0B 0A 00 00 00 00 11 02 3C 00 0D 0B 0A 00 00
											00 00 00 00 00 00 00 00 00 00 00 0C 00 00 40
					// 1220*2656
					39 00 00 40 00 00 05 2A 00 00 04 C3
					39 00 00 00 00 00 05 2B 00 00 0A 5F
					// VESA Setting
					39 00 00 40 00 00 02 90 03
					39 00 00 40 00 00 02 6F 01
					39 00 00 40 00 00 02 90 43
					39 00 00 40 00 00 13 91 89 28 00 10 C2 00 02 32 01 9C 00 08 06 67 05 92 10 E0
					// DC 120Hz
					39 00 00 40 00 00 02 2F 30
					39 00 00 00 00 00 02 6D 00
					// TE On
					39 00 00 00 00 00 02 35 00
					// DBV = 0
					39 00 00 00 00 00 03 51 00 00
					// idle_dimming_dbv = 0
					39 00 00 40 00 00 02 6F 04
					39 00 00 00 00 00 03 51 00 00
					// BCTRL = 1, DD = 0
					39 00 00 00 00 00 02 53 20
					// 0x00 Data remap off 0x0F Data remap on
					39 00 00 40 00 00 06 F0 55 AA 52 08 00
					39 00 00 40 00 00 02 6F 02
					39 00 00 40 00 00 02 B2 0F
 					// Skip mode setting
					39 00 00 40 00 00 04 8C 00 00 10
					39 00 00 40 00 00 03 5A 00 00
					39 00 00 00 00 00 02 2F 30
					// AP SPR
					39 00 00 40 00 00 06 F0 55 AA 52 08 03
					39 00 00 40 00 00 02 6F 09
					39 00 00 40 00 00 07 DE 10 34 25 30 14 25
					39 00 00 40 00 00 06 F0 55 AA 52 08 07
					39 00 00 40 00 00 06 B0 84 44 00 00 40
					39 00 00 40 00 00 07 B1 18 08 00 08 18 00
					39 00 00 00 00 00 13 91 AB F0 00 10 C1 00 01 CB 00 73 00 33 06 67 1F B0 11 40
					// AUTO 60hz Temp
					39 00 00 40 00 00 06 F0 55 AA 52 08 00
					15 00 00 40 00 00 02 6F 0E
					15 00 00 40 00 00 02 C0 00
					15 00 00 40 00 00 02 6F DE
					15 00 00 40 00 00 02 BA 00
					15 00 00 40 00 00 02 6F 04
					15 00 00 40 00 00 02 35 01
					15 00 00 40 00 00 02 6F 14
					15 00 00 40 00 00 02 35 00
					39 00 00 40 00 00 03 44 0A 60
					15 00 00 40 00 00 02 8C 00
					15 00 00 00 00 00 02 6D 0B
					// Still = 0 VDO no RAM
					39 00 00 00 00 00 02 18 00
					// GPO2 = Vsync
					39 00 00 40 00 00 06 F0 55 AA 52 08 00
					39 00 00 40 00 00 02 6F 02
					39 00 00 40 00 00 03 BE 4F 4A
					39 00 00 40 00 00 02 6F 0A
					39 00 00 00 00 00 02 BE 02
					// VDO with RAM
					39 00 00 40 00 00 06 F0 55 AA 52 08 01
					39 00 00 40 00 00 02 6F 17
					39 00 00 00 00 00 02 B8 07
					// GMA By Frame
					39 00 00 40 00 00 06 F0 55 AA 52 08 02
					39 00 00 00 00 00 02 CC 10
					// Idle Mode porch
					39 00 00 40 00 00 05 FF AA 55 A5 81
					39 00 00 40 00 00 02 6F 0F
					39 00 00 00 00 00 02 F5 0E
					// Demura on
					39 00 00 40 00 00 06 F0 55 AA 52 08 04
					39 00 00 00 00 00 02 CA 01
					// A3 Setting
					39 00 00 40 00 00 06 F0 55 AA 52 08 04
					39 00 00 40 00 00 02 6F 06
					39 00 00 40 00 00 02 B5 00
					39 00 00 40 00 00 05 FF AA 55 A5 81
					39 00 00 40 00 00 02 6F 0D
					39 00 00 40 00 00 02 FD 40
					39 00 00 40 00 00 07 51 00 00 00 00 00 00
					39 00 00 00 00 00 06 A3 84 02 5F 02 5F
					// Sleep Out
					05 00 00 00 5F 00 01 11
					// expand demura lut 16DBV*7Gray
					39 00 00 40 00 00 13 A3 84 02 5F 02 5F 02 04 B5 02 03 00 03 00 00 00 00 00 00
					39 00 00 40 00 00 02 6F 12
					39 00 00 40 00 00 0E A3 01 00 9D 00 00 AA 00 00 00 00 00 00 00
					39 00 00 40 00 00 02 6F 53
					39 00 00 40 00 00 0E A3 02 04 B5 02 03 00 0C 00 00 00 00 00 00
					39 00 00 40 00 00 02 6F 60
					39 00 00 00 00 00 0E A3 01 00 9D 00 00 AA 00 00 00 00 00 00 00
					// Display On
					05 00 00 00 00 00 01 29
					// ESD ERR Flag on
					39 00 00 40 00 00 06 F0 55 AA 52 08 00
					15 00 00 40 00 00 02 6F 05
					15 00 00 00 00 00 02 BE 08
					//OD code
					39 00 00 40 00 00 06 F0 55 AA 52 08 08
					15 00 00 40 00 00 02 6F 1B
					39 00 00 40 00 00 07 EB 34 E0 00 05 00 00
					//120Hz DC Skip Frame Rate
					39 00 00 40 00 00 06 F0 55 AA 52 08 00
					15 00 00 40 00 00 02 6F 5A
					39 00 00 00 00 00 09 D1 10 10 00 00 00 01 20 21
				];
				qcom,mdss-dsi-on-command-state = "dsi_lp_mode";
			};
			timing@wqhd_auto_120_to_1hz_index_8 {
				#include "dsi-panel-q200-42-02-0a-p21-prim-dsc-cmd-common.dtsi"
				cell-index = <8>;
				qcom,mdss-dsi-panel-framerate = <120>;
				/* ---------------------------- */
				/* | 15 - 14 | 13 - 7 | 6 - 0 | */
				/* ---------------------------- */
				/* |   mode  | sf fps | min fps| */
				/* ---------------------------- -*/
				/* mode: 1 idle, 2 auto, 3 qsync */
				/*   2 << 14 | 120 << 7 | 30     */
				qcom,mdss-dsi-h-sync-skew = <48158>;
				/* mode: 0 normal, 1 idle, 2 auto, 3 qsync, 4 diff, 5 test */
				mi,mdss-dsi-ddic-mode = "auto";
				mi,mdss-dsi-sf-framerate = <120>;
				mi,mdss-dsi-ddic-min-framerate = <1>;
				qcom,mdss-dsi-timing-switch-command = [
					// AUTO 120hz Temp
					39 00 00 40 00 00 06 F0 55 AA 52 08 00
					15 00 00 40 00 00 02 6F 0E
					15 00 00 40 00 00 02 C0 00
					15 00 00 40 00 00 02 6F DE
					15 00 00 40 00 00 02 BA 00
					15 00 00 40 00 00 02 6F 04
					15 00 00 40 00 00 02 35 00
					15 00 00 40 00 00 02 6F 14
					15 00 00 40 00 00 02 35 00
					39 00 00 40 00 00 03 44 0A 60
					15 00 00 40 00 00 02 8C 00
					15 00 00 00 00 00 02 6D 09
				];
				qcom,mdss-dsi-timing-switch-command-state = "dsi_hs_mode";
				mi,mdss-dsi-timing-switch-pwm-command = [
					// AUTO 120hz Temp
					39 00 00 40 00 00 06 F0 55 AA 52 08 00
					15 00 00 40 00 00 02 6F 0E
					15 00 00 40 00 00 02 C0 00
					15 00 00 40 00 00 02 6F DE
					15 00 00 40 00 00 02 BA 00
					15 00 00 40 00 00 02 6F 04
					15 00 00 40 00 00 02 35 00
					15 00 00 40 00 00 02 6F 14
					15 00 00 40 00 00 02 35 00
					39 00 00 40 00 00 03 44 0A 60
					15 00 00 40 00 00 02 8C 00
					15 00 00 00 00 00 02 6D 09
				];
				mi,mdss-dsi-timing-switch-pwm-command-state = "dsi_hs_mode";
				qcom,mdss-dsi-on-command = [
					// LCTC ON
					39 00 00 40 00 00 06 F0 55 AA 52 08 08
					15 00 00 40 00 00 02 BF 21
					// ACTC ON
					15 00 00 40 00 00 02 6F B7
					15 00 00 00 00 00 02 BF 11
					// OD ON
					39 00 00 40 00 00 06 F0 55 AA 52 08 08
					15 00 00 00 00 00 02 E0 01
					// VINT power domain
					39 00 00 40 00 00 06 F0 55 AA 52 08 01
					15 00 00 40 00 00 02 6F 49
					39 00 00 00 00 00 06 B9 01 22 00 EE EE
					// AOD pump
					39 00 00 40 00 00 06 F0 55 AA 52 08 01
					39 00 00 00 00 00 05 B2 00 00 FF 03
					// Data chopper setting
					39 00 00 40 00 00 06 F0 55 AA 52 08 01
					15 00 00 40 00 00 02 6F 23
					39 00 00 00 00 00 04 D9 CB 49 13
					// EM TH2 Duty Setting
					39 00 00 40 00 00 06 F0 55 AA 52 08 00
					39 00 00 40 00 00 02 6F 21
					39 00 00 40 00 00 09 B2 00 28 00 28 00 3C 00 28
					39 00 00 40 00 00 02 6F 75
					39 00 00 40 00 00 09 B2 00 28 00 28 00 3C 00 28
					39 00 00 40 00 00 02 6F 71
					39 00 00 00 00 00 03 B2 00 28
					// PMIC Fast discharge
					39 00 00 40 00 00 02 6F 51
					39 00 00 40 00 00 02 D5 02
					39 00 00 40 00 00 02 6F 54
					39 00 00 00 00 00 02 D5 1F
					// Switch VGMP by Fcon
					39 00 00 40 00 00 06 F0 55 AA 52 08 01
					39 00 00 40 00 00 02 6F 16
					39 00 00 00 00 00 05 C6 87 22 2C 2C
					// demura,FLASH CODE
					39 00 00 40 00 00 06 F0 55 AA 52 08 00
					39 00 00 40 00 00 02 C7 44
					39 00 00 40 00 00 02 6F 31
					39 00 00 40 00 00 03 C0 00 20
					39 00 00 40 00 00 02 6F 06
					39 00 00 40 00 00 03 C7 60 60
					39 00 00 40 00 00 02 6F 08
					39 00 00 40 00 00 03 C7 66 26
					39 00 00 40 00 00 06 F0 55 AA 52 08 04
					39 00 00 00 00 00 02 C0 20
					// SVM
					39 00 00 40 00 00 06 F0 55 AA 52 08 00
					39 00 00 40 00 00 02 6F 20
					39 00 00 40 00 00 02 B2 03
					39 00 00 40 00 00 06 F0 55 AA 52 08 01
					39 00 00 40 00 00 02 6F F0
					39 00 00 40 00 00 02 C0 F1
					39 00 00 40 00 00 02 6F F1
					39 00 00 40 00 00 03 C0 12 12
					39 00 00 40 00 00 02 6F F4
					39 00 00 40 00 00 03 C0 12 12
					39 00 00 40 00 00 02 6F 01
					39 00 00 40 00 00 04 CE 00 00 00
					39 00 00 40 00 00 02 6F 94
					39 00 00 40 00 00 04 E2 00 11 00
					39 00 00 40 00 00 02 6F 24
					39 00 00 40 00 00 13 E5 42 8C 94 90 92 07 42 8C 94 90 92 07 42 8C 94 90 92 07
					39 00 00 40 00 00 02 6F A7
					39 00 00 40 00 00 02 E7 C0
					39 00 00 40 00 00 02 6F DA
					39 00 00 40 00 00 03 E7 00 00
					39 00 00 40 00 00 06 F0 55 AA 52 08 01
					39 00 00 40 00 00 02 6F E3
					39 00 00 00 00 00 18 E5 FF FF FF FF 9B 9B 61 61 4D 4D 3A 3A 00 00 00 00 00 00 00 00 00 00 00
					// APL,Normal 32,HBM 8,APL 0
					39 00 00 40 00 00 06 F0 55 AA 52 08 00
					39 00 00 40 00 00 02 6F 78
					39 00 00 40 00 00 18 B0 11 00 2A 00 C2 01 DA 03 7C 05 B1 08 80 0B EE 0F FF 05 55 05 56 05 55
					39 00 00 40 00 00 02 6F 6F
					39 00 00 40 00 00 07 B0 02 62 04 C4 02 62
					39 00 00 40 00 00 06 F0 55 AA 52 08 08
					39 00 00 40 00 00 17 C1 9C FF CC FF FF CC FF FF CC FF FF DC FF FF DD FF FF FF 7F FF 0E FF
					39 00 00 40 00 00 02 6F 1D
					39 00 00 40 00 00 07 C1 00 FF FF 4F 00 FF
					39 00 00 40 00 00 02 6F 23
					39 00 00 40 00 00 15 C1 0C FF CC FF FF CC FF FF CC FF FF DC FF FF DD FF FF CF 7F 67
					39 00 00 40 00 00 02 6F 37
					39 00 00 40 00 00 15 C1 0C FF CC FF FF CC FF FF CC FF FF DC FF FF DD FF FF FF 7F FF
					39 00 00 40 00 00 02 6F 4B
					39 00 00 00 00 00 15 C1 0C FF CC FF FF CC FF FF CC FF FF DC FF FF DD FF FF CF 7F 67
					// Data Scaling DBV_TH
					39 00 00 00 00 00 2D BA 00 07 00 26 00 26 00 64 00 64 00 AC 00 AC 01 26 01 26 02 5F 02 5F 02 60 02 60 07 FB 07 FB 17 FE 17 FE 1F FF 1F FF 34 BC 34 BC 3F FE
					// ESD ERR Flag
					39 00 00 40 00 00 06 F0 55 AA 52 08 00
					39 00 00 40 00 00 03 BE 47 45
					15 00 00 40 00 00 02 6F 05
					15 00 00 40 00 00 02 BE 00
					15 00 00 40 00 00 02 6F 19
					39 00 00 00 00 00 05 BE 10 0A 00 9C
					// DVDD Low Voltage detect
					39 00 00 40 00 00 06 F0 55 AA 52 08 01
					15 00 00 40 00 00 02 6F 03
					15 00 00 00 00 00 02 C7 C7
					// ESD protect
					39 00 00 40 00 00 05 FF AA 55 A5 81
					39 00 00 40 00 00 02 6F 0F
					39 00 00 00 00 00 02 FD 80
					// video trim
					39 00 00 40 00 00 06 F0 55 AA 52 08 01
					39 00 00 40 00 00 37 C3 DD 29 02 6F E3 00 29 00 6F E3 00 3F 49 2E 3F 26 0F 3F 49 2E
											3F 26 0F 3F 49 2E 3F 26 0F 3F 49 2E 3F 26 0F 3F 49 2E 3F 26 0F 11 11 01 11 11 01 77 C0 AA 02 AA 02 00
					39 00 00 00 00 00 24 EA 11 02 3C 00 0D 0B 0A 00 00 00 00 11 02 3C 00 0D 0B 0A 00 00
											00 00 00 00 00 00 00 00 00 00 00 0C 00 00 40
					// 1220*2656
					39 00 00 40 00 00 05 2A 00 00 04 C3
					39 00 00 00 00 00 05 2B 00 00 0A 5F
					// VESA Setting
					39 00 00 40 00 00 02 90 03
					39 00 00 40 00 00 02 6F 01
					39 00 00 40 00 00 02 90 43
					39 00 00 40 00 00 13 91 89 28 00 10 C2 00 02 32 01 9C 00 08 06 67 05 92 10 E0
					// DC 120Hz
					39 00 00 40 00 00 02 2F 30
					39 00 00 00 00 00 02 6D 00
					// TE On
					39 00 00 00 00 00 02 35 00
					// DBV = 0
					39 00 00 00 00 00 03 51 00 00
					// idle_dimming_dbv = 0
					39 00 00 40 00 00 02 6F 04
					39 00 00 00 00 00 03 51 00 00
					// BCTRL = 1, DD = 0
					39 00 00 00 00 00 02 53 20
					// 0x00 Data remap off 0x0F Data remap on
					39 00 00 40 00 00 06 F0 55 AA 52 08 00
					39 00 00 40 00 00 02 6F 02
					39 00 00 40 00 00 02 B2 0F
 					// Skip mode setting
					39 00 00 40 00 00 04 8C 00 00 10
					39 00 00 40 00 00 03 5A 00 00
					39 00 00 00 00 00 02 2F 30
					// AP SPR
					39 00 00 40 00 00 06 F0 55 AA 52 08 03
					39 00 00 40 00 00 02 6F 09
					39 00 00 40 00 00 07 DE 10 34 25 30 14 25
					39 00 00 40 00 00 06 F0 55 AA 52 08 07
					39 00 00 40 00 00 06 B0 84 44 00 00 40
					39 00 00 40 00 00 07 B1 18 08 00 08 18 00
					39 00 00 00 00 00 13 91 AB F0 00 10 C1 00 01 CB 00 73 00 33 06 67 1F B0 11 40
					// AUTO 120hz Temp
					39 00 00 40 00 00 06 F0 55 AA 52 08 00
					15 00 00 40 00 00 02 6F 0E
					15 00 00 40 00 00 02 C0 00
					15 00 00 40 00 00 02 6F DE
					15 00 00 40 00 00 02 BA 00
					15 00 00 40 00 00 02 6F 04
					15 00 00 40 00 00 02 35 00
					15 00 00 40 00 00 02 6F 14
					15 00 00 40 00 00 02 35 00
					39 00 00 40 00 00 03 44 0A 60
					15 00 00 40 00 00 02 8C 00
					15 00 00 00 00 00 02 6D 09
					// Still = 0 VDO no RAM
					39 00 00 00 00 00 02 18 00
					// GPO2 = Vsync
					39 00 00 40 00 00 06 F0 55 AA 52 08 00
					39 00 00 40 00 00 02 6F 02
					39 00 00 40 00 00 03 BE 4F 4A
					39 00 00 40 00 00 02 6F 0A
					39 00 00 00 00 00 02 BE 02
					// VDO with RAM
					39 00 00 40 00 00 06 F0 55 AA 52 08 01
					39 00 00 40 00 00 02 6F 17
					39 00 00 00 00 00 02 B8 07
					// GMA By Frame
					39 00 00 40 00 00 06 F0 55 AA 52 08 02
					39 00 00 00 00 00 02 CC 10
					// Idle Mode porch
					39 00 00 40 00 00 05 FF AA 55 A5 81
					39 00 00 40 00 00 02 6F 0F
					39 00 00 00 00 00 02 F5 0E
					// Demura on
					39 00 00 40 00 00 06 F0 55 AA 52 08 04
					39 00 00 00 00 00 02 CA 01
					// A3 Setting
					39 00 00 40 00 00 06 F0 55 AA 52 08 04
					39 00 00 40 00 00 02 6F 06
					39 00 00 40 00 00 02 B5 00
					39 00 00 40 00 00 05 FF AA 55 A5 81
					39 00 00 40 00 00 02 6F 0D
					39 00 00 40 00 00 02 FD 40
					39 00 00 40 00 00 07 51 00 00 00 00 00 00
					39 00 00 00 00 00 06 A3 84 02 5F 02 5F
					// Sleep Out
					05 00 00 00 5F 00 01 11
					// expand demura lut 16DBV*7Gray
					39 00 00 40 00 00 13 A3 84 02 5F 02 5F 02 04 B5 02 03 00 03 00 00 00 00 00 00
					39 00 00 40 00 00 02 6F 12
					39 00 00 40 00 00 0E A3 01 00 9D 00 00 AA 00 00 00 00 00 00 00
					39 00 00 40 00 00 02 6F 53
					39 00 00 40 00 00 0E A3 02 04 B5 02 03 00 0C 00 00 00 00 00 00
					39 00 00 40 00 00 02 6F 60
					39 00 00 00 00 00 0E A3 01 00 9D 00 00 AA 00 00 00 00 00 00 00
					// Display On
					05 00 00 00 00 00 01 29
					// ESD ERR Flag on
					39 00 00 40 00 00 06 F0 55 AA 52 08 00
					15 00 00 40 00 00 02 6F 05
					15 00 00 00 00 00 02 BE 08
					//OD code
					39 00 00 40 00 00 06 F0 55 AA 52 08 08
					15 00 00 40 00 00 02 6F 1B
					39 00 00 40 00 00 07 EB 34 E0 00 05 00 00
					//120Hz DC Skip Frame Rate
					39 00 00 40 00 00 06 F0 55 AA 52 08 00
					15 00 00 40 00 00 02 6F 5A
					39 00 00 00 00 00 09 D1 10 10 00 00 00 01 20 21
				];
				qcom,mdss-dsi-on-command-state = "dsi_lp_mode";
			};
			//FOR PWM Qsync, 360hz TE
			timing@wqhd_qsync_120_to_1hz_index_9 {
				#include "dsi-panel-q200-42-02-0a-p21-prim-dsc-cmd-common.dtsi"
				cell-index = <9>;
				qcom,mdss-dsi-panel-framerate = <120>;
				qcom,dsi-qsync-mode-avr-step-fps = <360>;
				/* ---------------------------- */
				/* | 15 - 14 | 13 - 7 | 6 - 0 | */
				/* ---------------------------- */
				/* |   mode  | sf fps | min fps| */
				/* ---------------------------- -*/
				/* mode: 1 idle, 2 auto, 3 qsync */
				/*   3 << 14 | 120 << 7 | 1     */
				qcom,mdss-dsi-h-sync-skew = <64513>;
				/* mode: 0 normal, 1 idle, 2 auto, 3 qsync, 4 diff, 5 test */
				mi,mdss-dsi-ddic-mode = "qsync";
				mi,mdss-dsi-sf-framerate = <120>;
				mi,mdss-dsi-ddic-min-framerate = <1>;
				qcom,mdss-dsi-timing-switch-command = [
					//QSYNC 120HZ
					39 00 00 40 00 00 06 F0 55 AA 52 08 00
					15 00 00 40 00 00 02 6F 0E
					15 00 00 40 00 00 02 C0 00
					15 00 00 40 00 00 02 6F DE
					15 00 00 40 00 00 02 BA 00
					15 00 00 40 00 00 02 6F 04
					15 00 00 40 00 00 02 35 00
					15 00 00 40 00 00 02 6F 14
					15 00 00 40 00 00 02 35 6C
					39 00 00 40 00 00 03 44 0A 60
					15 00 00 40 00 00 02 8C 00
					15 00 00 00 00 00 02 6D 87 // qsync 360HZ TE
				];
				qcom,mdss-dsi-timing-switch-command-state = "dsi_hs_mode";
				mi,mdss-dsi-timing-switch-pwm-command = [
					//QSYNC 120HZ
					39 00 00 40 00 00 06 F0 55 AA 52 08 00
					15 00 00 40 00 00 02 6F 0E
					15 00 00 40 00 00 02 C0 00
					15 00 00 40 00 00 02 6F DE
					15 00 00 40 00 00 02 BA 00
					15 00 00 40 00 00 02 6F 04
					15 00 00 40 00 00 02 35 00
					15 00 00 40 00 00 02 6F 14
					15 00 00 40 00 00 02 35 6C
					39 00 00 40 00 00 03 44 0A 60
					15 00 00 40 00 00 02 8C 00
					15 00 00 00 00 00 02 6D 87 // qsync 360HZ TE
				];
				mi,mdss-dsi-timing-switch-pwm-command-state = "dsi_hs_mode";
				qcom,mdss-dsi-on-command = [
					// LCTC ON
					39 00 00 40 00 00 06 F0 55 AA 52 08 08
					15 00 00 40 00 00 02 BF 21
					// ACTC ON
					15 00 00 40 00 00 02 6F B7
					15 00 00 00 00 00 02 BF 11
					// OD ON
					39 00 00 40 00 00 06 F0 55 AA 52 08 08
					15 00 00 00 00 00 02 E0 01
					// VINT power domain
					39 00 00 40 00 00 06 F0 55 AA 52 08 01
					15 00 00 40 00 00 02 6F 49
					39 00 00 00 00 00 06 B9 01 22 00 EE EE
					// AOD pump
					39 00 00 40 00 00 06 F0 55 AA 52 08 01
					39 00 00 00 00 00 05 B2 00 00 FF 03
					// Data chopper setting
					39 00 00 40 00 00 06 F0 55 AA 52 08 01
					15 00 00 40 00 00 02 6F 23
					39 00 00 00 00 00 04 D9 CB 49 13
					// EM TH2 Duty Setting
					39 00 00 40 00 00 06 F0 55 AA 52 08 00
					39 00 00 40 00 00 02 6F 21
					39 00 00 40 00 00 09 B2 00 28 00 28 00 3C 00 28
					39 00 00 40 00 00 02 6F 75
					39 00 00 40 00 00 09 B2 00 28 00 28 00 3C 00 28
					39 00 00 40 00 00 02 6F 71
					39 00 00 00 00 00 03 B2 00 28
					// PMIC Fast discharge
					39 00 00 40 00 00 02 6F 51
					39 00 00 40 00 00 02 D5 02
					39 00 00 40 00 00 02 6F 54
					39 00 00 00 00 00 02 D5 1F
					// Switch VGMP by Fcon
					39 00 00 40 00 00 06 F0 55 AA 52 08 01
					39 00 00 40 00 00 02 6F 16
					39 00 00 00 00 00 05 C6 87 22 2C 2C
					// demura,FLASH CODE
					39 00 00 40 00 00 06 F0 55 AA 52 08 00
					39 00 00 40 00 00 02 C7 44
					39 00 00 40 00 00 02 6F 31
					39 00 00 40 00 00 03 C0 00 20
					39 00 00 40 00 00 02 6F 06
					39 00 00 40 00 00 03 C7 60 60
					39 00 00 40 00 00 02 6F 08
					39 00 00 40 00 00 03 C7 66 26
					39 00 00 40 00 00 06 F0 55 AA 52 08 04
					39 00 00 00 00 00 02 C0 20
					// SVM
					39 00 00 40 00 00 06 F0 55 AA 52 08 00
					39 00 00 40 00 00 02 6F 20
					39 00 00 40 00 00 02 B2 03
					39 00 00 40 00 00 06 F0 55 AA 52 08 01
					39 00 00 40 00 00 02 6F F0
					39 00 00 40 00 00 02 C0 F1
					39 00 00 40 00 00 02 6F F1
					39 00 00 40 00 00 03 C0 12 12
					39 00 00 40 00 00 02 6F F4
					39 00 00 40 00 00 03 C0 12 12
					39 00 00 40 00 00 02 6F 01
					39 00 00 40 00 00 04 CE 00 00 00
					39 00 00 40 00 00 02 6F 94
					39 00 00 40 00 00 04 E2 00 11 00
					39 00 00 40 00 00 02 6F 24
					39 00 00 40 00 00 13 E5 42 8C 94 90 92 07 42 8C 94 90 92 07 42 8C 94 90 92 07
					39 00 00 40 00 00 02 6F A7
					39 00 00 40 00 00 02 E7 C0
					39 00 00 40 00 00 02 6F DA
					39 00 00 40 00 00 03 E7 00 00
					39 00 00 40 00 00 06 F0 55 AA 52 08 01
					39 00 00 40 00 00 02 6F E3
					39 00 00 00 00 00 18 E5 FF FF FF FF 9B 9B 61 61 4D 4D 3A 3A 00 00 00 00 00 00 00 00 00 00 00
					// APL,Normal 32,HBM 8,APL 0
					39 00 00 40 00 00 06 F0 55 AA 52 08 00
					39 00 00 40 00 00 02 6F 78
					39 00 00 40 00 00 18 B0 11 00 2A 00 C2 01 DA 03 7C 05 B1 08 80 0B EE 0F FF 05 55 05 56 05 55
					39 00 00 40 00 00 02 6F 6F
					39 00 00 40 00 00 07 B0 02 62 04 C4 02 62
					39 00 00 40 00 00 06 F0 55 AA 52 08 08
					39 00 00 40 00 00 17 C1 9C FF CC FF FF CC FF FF CC FF FF DC FF FF DD FF FF FF 7F FF 0E FF
					39 00 00 40 00 00 02 6F 1D
					39 00 00 40 00 00 07 C1 00 FF FF 4F 00 FF
					39 00 00 40 00 00 02 6F 23
					39 00 00 40 00 00 15 C1 0C FF CC FF FF CC FF FF CC FF FF DC FF FF DD FF FF CF 7F 67
					39 00 00 40 00 00 02 6F 37
					39 00 00 40 00 00 15 C1 0C FF CC FF FF CC FF FF CC FF FF DC FF FF DD FF FF FF 7F FF
					39 00 00 40 00 00 02 6F 4B
					39 00 00 00 00 00 15 C1 0C FF CC FF FF CC FF FF CC FF FF DC FF FF DD FF FF CF 7F 67
					// Data Scaling DBV_TH
					39 00 00 00 00 00 2D BA 00 07 00 26 00 26 00 64 00 64 00 AC 00 AC 01 26 01 26 02 5F 02 5F 02 60 02 60 07 FB 07 FB 17 FE 17 FE 1F FF 1F FF 34 BC 34 BC 3F FE
					// ESD ERR Flag
					39 00 00 40 00 00 06 F0 55 AA 52 08 00
					39 00 00 40 00 00 03 BE 47 45
					15 00 00 40 00 00 02 6F 05
					15 00 00 40 00 00 02 BE 00
					15 00 00 40 00 00 02 6F 19
					39 00 00 00 00 00 05 BE 10 0A 00 9C
					// DVDD Low Voltage detect
					39 00 00 40 00 00 06 F0 55 AA 52 08 01
					15 00 00 40 00 00 02 6F 03
					15 00 00 00 00 00 02 C7 C7
					// ESD protect
					39 00 00 40 00 00 05 FF AA 55 A5 81
					39 00 00 40 00 00 02 6F 0F
					39 00 00 00 00 00 02 FD 80
					// video trim
					39 00 00 40 00 00 06 F0 55 AA 52 08 01
					39 00 00 40 00 00 37 C3 DD 29 02 6F E3 00 29 00 6F E3 00 3F 49 2E 3F 26 0F 3F 49 2E
											3F 26 0F 3F 49 2E 3F 26 0F 3F 49 2E 3F 26 0F 3F 49 2E 3F 26 0F 11 11 01 11 11 01 77 C0 AA 02 AA 02 00
					39 00 00 00 00 00 24 EA 11 02 3C 00 0D 0B 0A 00 00 00 00 11 02 3C 00 0D 0B 0A 00 00
											00 00 00 00 00 00 00 00 00 00 00 0C 00 00 40
					// 1220*2656
					39 00 00 40 00 00 05 2A 00 00 04 C3
					39 00 00 00 00 00 05 2B 00 00 0A 5F
					// VESA Setting
					39 00 00 40 00 00 02 90 03
					39 00 00 40 00 00 02 6F 01
					39 00 00 40 00 00 02 90 43
					39 00 00 40 00 00 13 91 89 28 00 10 C2 00 02 32 01 9C 00 08 06 67 05 92 10 E0
					// DC 120Hz
					39 00 00 40 00 00 02 2F 30
					39 00 00 00 00 00 02 6D 00
					// TE On
					39 00 00 00 00 00 02 35 00
					// DBV = 0
					39 00 00 00 00 00 03 51 00 00
					// idle_dimming_dbv = 0
					39 00 00 40 00 00 02 6F 04
					39 00 00 00 00 00 03 51 00 00
					// BCTRL = 1, DD = 0
					39 00 00 00 00 00 02 53 20
					// 0x00 Data remap off 0x0F Data remap on
					39 00 00 40 00 00 06 F0 55 AA 52 08 00
					39 00 00 40 00 00 02 6F 02
					39 00 00 40 00 00 02 B2 0F
 					// Skip mode setting
					39 00 00 40 00 00 04 8C 00 00 10
					39 00 00 40 00 00 03 5A 00 00
					39 00 00 00 00 00 02 2F 30
					// AP SPR
					39 00 00 40 00 00 06 F0 55 AA 52 08 03
					39 00 00 40 00 00 02 6F 09
					39 00 00 40 00 00 07 DE 10 34 25 30 14 25
					39 00 00 40 00 00 06 F0 55 AA 52 08 07
					39 00 00 40 00 00 06 B0 84 44 00 00 40
					39 00 00 40 00 00 07 B1 18 08 00 08 18 00
					39 00 00 00 00 00 13 91 AB F0 00 10 C1 00 01 CB 00 73 00 33 06 67 1F B0 11 40
					//QSYNC 120HZ
					39 00 00 40 00 00 06 F0 55 AA 52 08 00
					15 00 00 40 00 00 02 6F 0E
					15 00 00 40 00 00 02 C0 00
					15 00 00 40 00 00 02 6F DE
					15 00 00 40 00 00 02 BA 00
					15 00 00 40 00 00 02 6F 04
					15 00 00 40 00 00 02 35 00
					15 00 00 40 00 00 02 6F 14
					15 00 00 40 00 00 02 35 6C
					39 00 00 40 00 00 03 44 0A 60
					15 00 00 40 00 00 02 8C 00
					15 00 00 00 00 00 02 6D 87 // qsync 360HZ TE
					// Still = 0 VDO no RAM
					39 00 00 00 00 00 02 18 00
					// GPO2 = Vsync
					39 00 00 40 00 00 06 F0 55 AA 52 08 00
					39 00 00 40 00 00 02 6F 02
					39 00 00 40 00 00 03 BE 4F 4A
					39 00 00 40 00 00 02 6F 0A
					39 00 00 00 00 00 02 BE 02
					// VDO with RAM
					39 00 00 40 00 00 06 F0 55 AA 52 08 01
					39 00 00 40 00 00 02 6F 17
					39 00 00 00 00 00 02 B8 07
					// GMA By Frame
					39 00 00 40 00 00 06 F0 55 AA 52 08 02
					39 00 00 00 00 00 02 CC 10
					// Idle Mode porch
					39 00 00 40 00 00 05 FF AA 55 A5 81
					39 00 00 40 00 00 02 6F 0F
					39 00 00 00 00 00 02 F5 0E
					// Demura on
					39 00 00 40 00 00 06 F0 55 AA 52 08 04
					39 00 00 00 00 00 02 CA 01
					// A3 Setting
					39 00 00 40 00 00 06 F0 55 AA 52 08 04
					39 00 00 40 00 00 02 6F 06
					39 00 00 40 00 00 02 B5 00
					39 00 00 40 00 00 05 FF AA 55 A5 81
					39 00 00 40 00 00 02 6F 0D
					39 00 00 40 00 00 02 FD 40
					39 00 00 40 00 00 07 51 00 00 00 00 00 00
					39 00 00 00 00 00 06 A3 84 02 5F 02 5F
					// Sleep Out
					05 00 00 00 5F 00 01 11
					// expand demura lut 16DBV*7Gray
					39 00 00 40 00 00 13 A3 84 02 5F 02 5F 02 04 B5 02 03 00 03 00 00 00 00 00 00
					39 00 00 40 00 00 02 6F 12
					39 00 00 40 00 00 0E A3 01 00 9D 00 00 AA 00 00 00 00 00 00 00
					39 00 00 40 00 00 02 6F 53
					39 00 00 40 00 00 0E A3 02 04 B5 02 03 00 0C 00 00 00 00 00 00
					39 00 00 40 00 00 02 6F 60
					39 00 00 00 00 00 0E A3 01 00 9D 00 00 AA 00 00 00 00 00 00 00
					// Display On
					05 00 00 00 00 00 01 29
					// ESD ERR Flag on
					39 00 00 40 00 00 06 F0 55 AA 52 08 00
					15 00 00 40 00 00 02 6F 05
					15 00 00 00 00 00 02 BE 08
					//OD code
					39 00 00 40 00 00 06 F0 55 AA 52 08 08
					15 00 00 40 00 00 02 6F 1B
					39 00 00 40 00 00 07 EB 34 E0 00 05 00 00
					//120Hz DC Skip Frame Rate
					39 00 00 40 00 00 06 F0 55 AA 52 08 00
					15 00 00 40 00 00 02 6F 5A
					39 00 00 00 00 00 09 D1 10 10 00 00 00 01 20 21
				];
				qcom,mdss-dsi-on-command-state = "dsi_lp_mode";
			};
		};
	};
};
&dsi_q200_42_02_0a_p21_prim_dsc_cmd {
	qcom,panel-supply-entries = <&dsi_panel_pwr_supply_q200>;
	qcom,mdss-dsi-bl-pmic-control-type = "bl_ctrl_dcs";
	qcom,mdss-dsi-bl-min-level = <7>;
	qcom,mdss-dsi-bl-max-level = <16383>;
	qcom,bl-dsc-cmd-state = "dsi_hs_mode";
	qcom,mdss-brightness-max-level = <16383>;
	qcom,mdss-brightness-init-level = <916>;
	qcom,platform-reset-gpio = <&tlmm 98 0>;
	qcom,platform-pmic-reset-gpio = <&tlmm 171 0>;

	mi,panel-id = <0x51323030 0x5042020A>;

	/* IRQF_ONESHOT | IRQF_TRIGGER_HEIGH */
	mi,esd-err-irq-gpio = <&tlmm 97 0x2004>;
	mi,esd-err-irq-gpio-flag = <0x2004>;

	mi,pmic-reset-gpio-always-on-flag;

	mi,mdss-dsi-panel-wp-read-command = [06 01 00 02 00 00 01 A3];
	mi,mdss-dsi-panel-wp-read-command-state = "dsi_hs_mode";
	mi,mdss-dsi-panel-wp-read-pre-tx-command = [39 00 00 00 00 00 02 6F 7A];
	mi,mdss-dsi-panel-wp-read-pre-tx-command-state = "dsi_hs_mode";
	mi,mdss-dsi-panel-wp-read-length = <8>;

	mi,mdss-dsi-panel-cell-id-read-command = [06 01 00 00 00 00 01 EB];
	mi,mdss-dsi-panel-cell-id-read-pre-tx-command = [
		39 00 00 40 00 00 06 F0 55 AA 52 08 00
		39 00 00 00 00 00 02 EA 10];
	mi,mdss-dsi-panel-cell-id-read-pre-tx-command-state = "dsi_hs_mode";
	mi,mdss-dsi-panel-cell-id-read-command-state = "dsi_hs_mode";
	mi,mdss-dsi-panel-cell-id-read-length = <13>;

	mi,panel-build-id-read-needed;
	mi,panel-build-id-read-length = <1>;
	mi,mdss-dsi-panel-build-id-read-command = [06 01 00 00 00 00 01 DB];
	mi,mdss-dsi-panel-build-id-read-command-state = "dsi_hs_mode";

	mi,flatmode-status-check-enabled;
	mi,mdss-dsi-panel-flatmode-status-command = [
		06 01 00 01 00 00 01 5F
	];
	mi,mdss-dsi-panel-flatmode-status-command-state = "dsi_hs_mode";
	mi,mdss-dsi-panel-flatmode-status-read-length = <1>;
	mi,mdss-dsi-panel-flatmode-on-status-value = <0x00>;

	mi,mdss-dsi-fac-bl-max-level = <8191>;
	mi,mdss-fac-brightness-max-level = <8191>;

	mi,doze-hbm-dbv-level = <412>;
	mi,doze-lbm-dbv-level = <35>;

	mi,max-brightness-normal = <5460>;

	mi,mdss-dsi-panel-dc-demura-threshold = <607>;
	mi,dc-feature-enabled;
	mi,default-dc-flag;
	mi,ddic-round-corner-enabled;

	qcom,ulps-enabled;
	qcom,dsi-select-clocks = "pll_byte_clk0", "pll_dsi_clk0";
	qcom,mdss-dsi-clk-strength = <0x88>;
};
